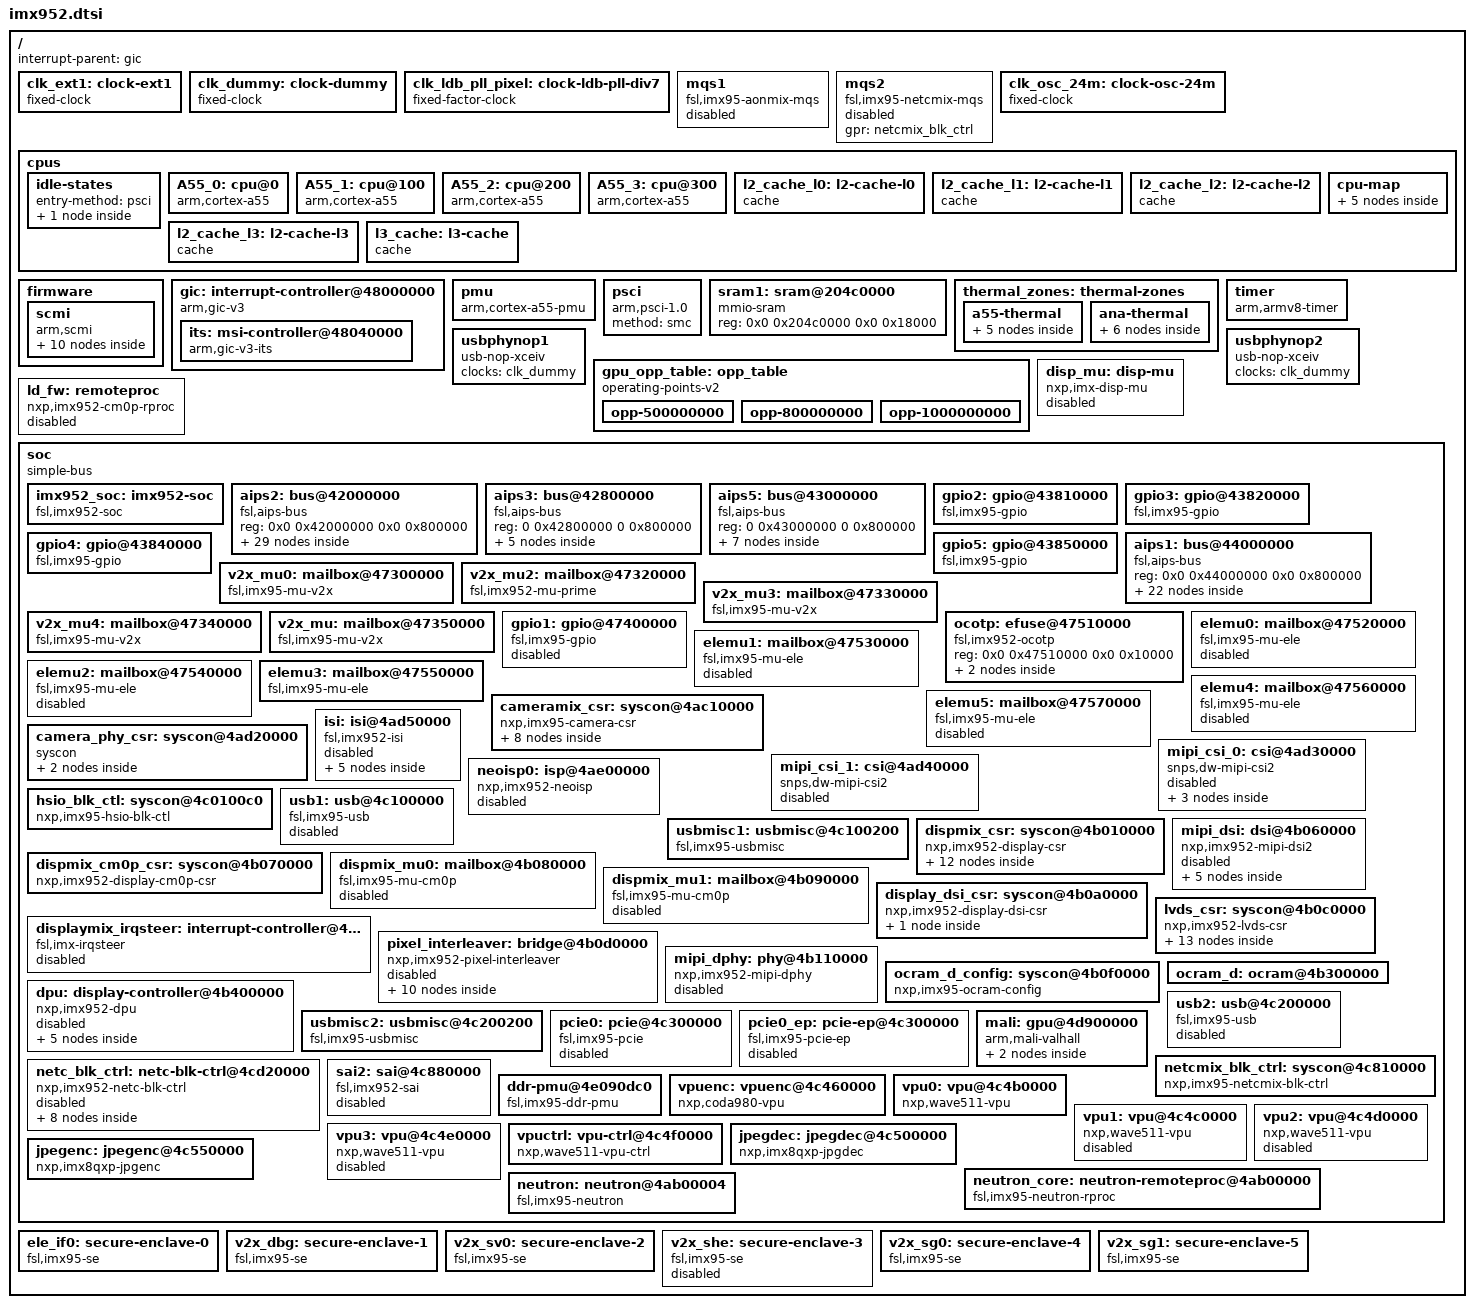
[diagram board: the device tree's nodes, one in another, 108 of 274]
// SPDX-License-Identifier: (GPL-2.0-only OR MIT)
/*
 * Copyright 2025-2026 NXP
 */

#include <dt-bindings/clock/nxp,imx952-clock.h>
#include <dt-bindings/dma/fsl-edma.h>
#include <dt-bindings/gpio/gpio.h>
#include <dt-bindings/interrupt-controller/arm-gic.h>
#include <dt-bindings/thermal/thermal.h>

#include "imx952-clock.h"
#include "imx952-pinfunc.h"
#include "imx952-power.h"

/ {
	interrupt-parent = <&gic>;
	#address-cells = <2>;
	#size-cells = <2>;

	clk_ext1: clock-ext1 {
		compatible = "fixed-clock";
		#clock-cells = <0>;
		clock-frequency = <133000000>;
		clock-output-names = "clk_ext1";
	};

	clk_dummy: clock-dummy {
		compatible = "fixed-clock";
		#clock-cells = <0>;
		clock-frequency = <0>;
		clock-output-names = "dummy";
	};

	clk_ldb_pll_pixel: clock-ldb-pll-div7 {
		compatible = "fixed-factor-clock";
		clocks = <&scmi_clk IMX952_CLK_LDBPLL>;
		#clock-cells = <0>;
		clock-div = <7>;
		clock-mult = <1>;
		clock-output-names = "ldb_pll_div7";
	};

	mqs1: mqs1 {
		compatible = "fsl,imx95-aonmix-mqs";
		status = "disabled";
	};

	mqs2: mqs2 {
		compatible = "fsl,imx95-netcmix-mqs";
		gpr = <&netcmix_blk_ctrl>;
		status = "disabled";
	};

	clk_osc_24m: clock-osc-24m {
		compatible = "fixed-clock";
		#clock-cells = <0>;
		clock-frequency = <24000000>;
		clock-output-names = "osc_24m";
	};

	cpus {
		#address-cells = <1>;
		#size-cells = <0>;

		idle-states {
			entry-method = "psci";

			cpu_pd_wait: cpu-pd-wait {
				compatible = "arm,idle-state";
				arm,psci-suspend-param = <0x0010033>;
				local-timer-stop;
				entry-latency-us = <1000>;
				exit-latency-us = <700>;
				min-residency-us = <2700>;
				wakeup-latency-us = <1500>;
			};
		};

		A55_0: cpu@0 {
			device_type = "cpu";
			compatible = "arm,cortex-a55";
			reg = <0x0>;
			enable-method = "psci";
			#cooling-cells = <2>;
			cpu-idle-states = <&cpu_pd_wait>;
			power-domains = <&scmi_perf IMX952_PERF_A55>;
			power-domain-names = "perf";
			i-cache-size = <32768>;
			i-cache-line-size = <64>;
			i-cache-sets = <128>;
			d-cache-size = <32768>;
			d-cache-line-size = <64>;
			d-cache-sets = <128>;
			next-level-cache = <&l2_cache_l0>;
		};

		A55_1: cpu@100 {
			device_type = "cpu";
			compatible = "arm,cortex-a55";
			reg = <0x100>;
			enable-method = "psci";
			#cooling-cells = <2>;
			cpu-idle-states = <&cpu_pd_wait>;
			power-domains = <&scmi_perf IMX952_PERF_A55>;
			power-domain-names = "perf";
			i-cache-size = <32768>;
			i-cache-line-size = <64>;
			i-cache-sets = <128>;
			d-cache-size = <32768>;
			d-cache-line-size = <64>;
			d-cache-sets = <128>;
			next-level-cache = <&l2_cache_l1>;
		};

		A55_2: cpu@200 {
			device_type = "cpu";
			compatible = "arm,cortex-a55";
			reg = <0x200>;
			enable-method = "psci";
			#cooling-cells = <2>;
			cpu-idle-states = <&cpu_pd_wait>;
			power-domains = <&scmi_perf IMX952_PERF_A55>;
			power-domain-names = "perf";
			i-cache-size = <32768>;
			i-cache-line-size = <64>;
			i-cache-sets = <128>;
			d-cache-size = <32768>;
			d-cache-line-size = <64>;
			d-cache-sets = <128>;
			next-level-cache = <&l2_cache_l2>;
		};

		A55_3: cpu@300 {
			device_type = "cpu";
			compatible = "arm,cortex-a55";
			reg = <0x300>;
			enable-method = "psci";
			#cooling-cells = <2>;
			cpu-idle-states = <&cpu_pd_wait>;
			power-domains = <&scmi_perf IMX952_PERF_A55>;
			power-domain-names = "perf";
			i-cache-size = <32768>;
			i-cache-line-size = <64>;
			i-cache-sets = <128>;
			d-cache-size = <32768>;
			d-cache-line-size = <64>;
			d-cache-sets = <128>;
			next-level-cache = <&l2_cache_l3>;
		};

		l2_cache_l0: l2-cache-l0 {
			compatible = "cache";
			cache-size = <65536>;
			cache-line-size = <64>;
			cache-sets = <256>;
			cache-level = <2>;
			cache-unified;
			next-level-cache = <&l3_cache>;
		};

		l2_cache_l1: l2-cache-l1 {
			compatible = "cache";
			cache-size = <65536>;
			cache-line-size = <64>;
			cache-sets = <256>;
			cache-level = <2>;
			cache-unified;
			next-level-cache = <&l3_cache>;
		};

		l2_cache_l2: l2-cache-l2 {
			compatible = "cache";
			cache-size = <65536>;
			cache-line-size = <64>;
			cache-sets = <256>;
			cache-level = <2>;
			cache-unified;
			next-level-cache = <&l3_cache>;
		};

		l2_cache_l3: l2-cache-l3 {
			compatible = "cache";
			cache-size = <65536>;
			cache-line-size = <64>;
			cache-sets = <256>;
			cache-level = <2>;
			cache-unified;
			next-level-cache = <&l3_cache>;
		};

		l3_cache: l3-cache {
			compatible = "cache";
			cache-size = <524288>;
			cache-line-size = <64>;
			cache-sets = <512>;
			cache-level = <3>;
			cache-unified;
		};

		cpu-map {
			cluster0 {
				core0 {
					cpu = <&A55_0>;
				};

				core1 {
					cpu = <&A55_1>;
				};

				core2 {
					cpu = <&A55_2>;
				};

				core3 {
					cpu = <&A55_3>;
				};
			};
		};
	};

	firmware {
		scmi {
			compatible = "arm,scmi";
			mboxes = <&mu2 5 0>, <&mu2 3 0>, <&mu2 3 1>, <&mu2 5 1>;
			shmem = <&scmi_buf0>, <&scmi_buf1>;
			#address-cells = <1>;
			#size-cells = <0>;
			arm,max-rx-timeout-ms = <5000>;

			scmi_devpd: protocol@11 {
				reg = <0x11>;
				#power-domain-cells = <1>;
			};

			scmi_sys_power: protocol@12 {
				reg = <0x12>;
			};

			scmi_perf: protocol@13 {
				reg = <0x13>;
				#power-domain-cells = <1>;
			};

			scmi_clk: protocol@14 {
				reg = <0x14>;
				#clock-cells = <1>;
			};

			scmi_sensor: protocol@15 {
				reg = <0x15>;
				#thermal-sensor-cells = <1>;
			};

			scmi_iomuxc: protocol@19 {
				reg = <0x19>;
			};

			scmi_lmm: protocol@80 {
				reg = <0x80>;
			};

			scmi_bbm: protocol@81 {
				reg = <0x81>;
			};

			scmi_cpu: protocol@82 {
				reg = <0x82>;
			};

			scmi_misc: protocol@84 {
				reg = <0x84>;
			};
		};
	};

	gic: interrupt-controller@48000000 {
		compatible = "arm,gic-v3";
		reg = <0 0x48000000 0 0x10000>,
		      <0 0x48060000 0 0xc0000>;
		interrupts = <GIC_PPI 9 IRQ_TYPE_LEVEL_HIGH>;
		interrupt-parent = <&gic>;
		interrupt-controller;
		#interrupt-cells = <3>;
		dma-noncoherent;
		#address-cells = <2>;
		#size-cells = <2>;
		ranges;

		its: msi-controller@48040000 {
			compatible = "arm,gic-v3-its";
			reg = <0 0x48040000 0 0x20000>;
			msi-controller;
			#msi-cells = <1>;
			dma-noncoherent;
		};
	};

	pmu {
		compatible = "arm,cortex-a55-pmu";
		interrupts = <GIC_PPI 7 (GIC_CPU_MASK_SIMPLE(6) | IRQ_TYPE_LEVEL_HIGH)>;
	};

	psci {
		compatible = "arm,psci-1.0";
		method = "smc";
	};

	sram1: sram@204c0000 {
		compatible = "mmio-sram";
		reg = <0x0 0x204c0000 0x0 0x18000>;
		ranges = <0x0 0x0 0x204c0000 0x18000>;
		#address-cells = <1>;
		#size-cells = <1>;
	};

	thermal_zones: thermal-zones {
		a55-thermal {
			polling-delay-passive = <250>;
			polling-delay = <2000>;
			thermal-sensors = <&scmi_sensor 1>;
			trips {
				cpu_alert0: trip0 {
					temperature = <105000>;
					hysteresis = <2000>;
					type = "passive";
				};

				cpu_crit0: trip1 {
					temperature = <125000>;
					hysteresis = <2000>;
					type = "critical";
				};
			};

			cooling-maps {
				map0 {
					trip = <&cpu_alert0>;
					cooling-device =
						<&A55_0 THERMAL_NO_LIMIT THERMAL_NO_LIMIT>,
						<&A55_1 THERMAL_NO_LIMIT THERMAL_NO_LIMIT>,
						<&A55_2 THERMAL_NO_LIMIT THERMAL_NO_LIMIT>,
						<&A55_3 THERMAL_NO_LIMIT THERMAL_NO_LIMIT>;
				};
			};
		};

		ana-thermal {
			polling-delay-passive = <250>;
			polling-delay = <2000>;
			thermal-sensors = <&scmi_sensor 0>;
			trips {
				ana_alert: trip0 {
					temperature = <105000>;
					hysteresis = <2000>;
					type = "passive";
				};

				ana_crit0: trip1 {
					temperature = <125000>;
					hysteresis = <2000>;
					type = "critical";
				};
			};

			cooling-maps {
				map0 {
					trip = <&ana_alert>;
					cooling-device =
						<&A55_0 THERMAL_NO_LIMIT THERMAL_NO_LIMIT>,
						<&A55_1 THERMAL_NO_LIMIT THERMAL_NO_LIMIT>,
						<&A55_2 THERMAL_NO_LIMIT THERMAL_NO_LIMIT>,
						<&A55_3 THERMAL_NO_LIMIT THERMAL_NO_LIMIT>,
						<&mali  THERMAL_NO_LIMIT THERMAL_NO_LIMIT>;
				};
				map1 {
					trip = <&ana_crit0>;
					cooling-device = <&mali THERMAL_NO_LIMIT 1>;
				};
			};
		};
	};

	timer {
		compatible = "arm,armv8-timer";
		interrupts = <GIC_PPI 13 (GIC_CPU_MASK_SIMPLE(6) | IRQ_TYPE_LEVEL_LOW)>,
			     <GIC_PPI 14 (GIC_CPU_MASK_SIMPLE(6) | IRQ_TYPE_LEVEL_LOW)>,
			     <GIC_PPI 11 (GIC_CPU_MASK_SIMPLE(6) | IRQ_TYPE_LEVEL_LOW)>,
			     <GIC_PPI 10 (GIC_CPU_MASK_SIMPLE(6) | IRQ_TYPE_LEVEL_LOW)>;
		clock-frequency = <24000000>;
		arm,no-tick-in-suspend;
		interrupt-parent = <&gic>;
	};

	usbphynop1: usbphynop1 {
		compatible = "usb-nop-xceiv";
		#phy-cells = <0>;
		clocks = <&clk_dummy>;
		clock-names = "main_clk";
	};

	usbphynop2: usbphynop2 {
		compatible = "usb-nop-xceiv";
		#phy-cells = <0>;
		clocks = <&clk_dummy>;
		clock-names = "main_clk";
	};

	gpu_opp_table: opp_table {
		compatible = "operating-points-v2", "operating-points-v2-mali";

		opp-500000000 {
			opp-hz = /bits/ 64 <500000000>;
			opp-hz-real = /bits/ 64 <500000000>;
			opp-microvolt = <920000>;
		};

		opp-800000000 {
			opp-hz = /bits/ 64 <800000000>;
			opp-hz-real = /bits/ 64 <800000000>;
			opp-microvolt = <920000>;
		};

		opp-1000000000 {
			opp-hz = /bits/ 64 <1000000000>;
			opp-hz-real = /bits/ 64 <1000000000>;
			opp-microvolt = <920000>;
		};
	};

	disp_mu: disp-mu {
		compatible = "nxp,imx-disp-mu";
		mbox-names = "tx", "rx";
		mboxes = <&dispmix_mu1 0 0>,
			 <&dispmix_mu1 1 0>;
		status = "disabled";
	};

	ld_fw: remoteproc {
		compatible = "nxp,imx952-cm0p-rproc";
		firmware-name = "imx9xm0p_ld_fw.bin";
		clocks = <&dispmix_cm0p_csr IMX952_CLK_CM0P_GATE_SEL>,
			 <&scmi_clk IMX952_CLK_CGC_DISPOCRAM>,
			 <&scmi_clk IMX952_CLK_DISPLPSPI>;
		clock-names = "cm0p", "ocram", "lpspi";
		assigned-clocks = <&scmi_clk IMX952_CLK_DISPLPSPI>;
		assigned-clock-parents = <&scmi_clk IMX952_CLK_SYSPLL1_PFD1_DIV2>;
		assigned-clock-rates = <20000000>;
		power-domains = <&scmi_devpd IMX952_PD_DISPLAY>;
		memory-region = <&ocram_d>;

		nxp,cm0p-ctrl = <&dispmix_cm0p_csr>;
		nxp,ocram-ctrl = <&dispmix_csr>;
		nxp,ocram-cfg = <&ocram_d_config>;

		status = "disabled";
	};

	soc {
		compatible = "simple-bus";
		#address-cells = <2>;
		#size-cells = <2>;
		ranges;

		imx952_soc: imx952-soc {
			compatible = "fsl,imx952-soc";
		};

		aips2: bus@42000000 {
			compatible = "fsl,aips-bus", "simple-bus";
			reg = <0x0 0x42000000 0x0 0x800000>;
			ranges = <0x42000000 0x0 0x42000000 0x8000000>,
				 <0x28000000 0x0 0x28000000 0x10000000>;
			#address-cells = <1>;
			#size-cells = <1>;

			mu7: mailbox@42050000 {
				compatible = "fsl,imx95-mu";
				reg = <0x42050000 0x10000>;
				interrupts = <GIC_SPI 234 IRQ_TYPE_LEVEL_HIGH>;
				clocks = <&scmi_clk IMX952_CLK_BUSWAKEUP>;
				#mbox-cells = <2>;
				status = "disabled";
			};

			wdog3: watchdog@420b0000 {
				compatible = "fsl,imx93-wdt";
				reg = <0x420b0000 0x10000>;
				interrupts = <GIC_SPI 77 IRQ_TYPE_LEVEL_HIGH>;
				clocks = <&scmi_clk IMX952_CLK_BUSWAKEUP>;
				timeout-sec = <40>;
				status = "disabled";
			};

			tpm3: pwm@42100000 {
				compatible = "fsl,imx7ulp-pwm";
				reg = <0x42100000 0x1000>;
				clocks = <&scmi_clk IMX952_CLK_BUSWAKEUP>;
				#pwm-cells = <3>;
				status = "disabled";
			};

			tpm4: pwm@42110000 {
				compatible = "fsl,imx7ulp-pwm";
				reg = <0x42110000 0x1000>;
				clocks = <&scmi_clk IMX952_CLK_TPM4>;
				#pwm-cells = <3>;
				status = "disabled";
			};

			tpm5: pwm@42120000 {
				compatible = "fsl,imx7ulp-pwm";
				reg = <0x42120000 0x1000>;
				clocks = <&scmi_clk IMX952_CLK_TPM5>;
				#pwm-cells = <3>;
				status = "disabled";
			};

			tpm6: pwm@42130000 {
				compatible = "fsl,imx7ulp-pwm";
				reg = <0x42130000 0x1000>;
				clocks = <&scmi_clk IMX952_CLK_TPM6>;
				#pwm-cells = <3>;
				status = "disabled";
			};

			i3c2: i3c@42140000 {
				compatible = "silvaco,i3c-master-v1";
				reg = <0x42140000 0x10000>;
				interrupts = <GIC_SPI 57 IRQ_TYPE_LEVEL_HIGH>;
				#address-cells = <3>;
				#size-cells = <0>;
				clocks = <&scmi_clk IMX952_CLK_BUSWAKEUP>,
					 <&scmi_clk IMX952_CLK_I3C2SLOW>,
					 <&clk_dummy>;
				clock-names = "pclk", "fast_clk", "slow_clk";
				status = "disabled";
			};

			lpi2c3: i2c@42150000 {
				compatible = "fsl,imx95-lpi2c", "fsl,imx7ulp-lpi2c";
				reg = <0x42150000 0x10000>;
				interrupts = <GIC_SPI 58 IRQ_TYPE_LEVEL_HIGH>;
				clocks = <&scmi_clk IMX952_CLK_LPI2C3>,
					 <&scmi_clk IMX952_CLK_BUSWAKEUP>;
				clock-names = "per", "ipg";
				#address-cells = <1>;
				#size-cells = <0>;
				dmas = <&edma2 8 0 0>, <&edma2 9 0 FSL_EDMA_RX>;
				dma-names = "tx", "rx";
				status = "disabled";
			};

			lpi2c4: i2c@42160000 {
				compatible = "fsl,imx95-lpi2c", "fsl,imx7ulp-lpi2c";
				reg = <0x42160000 0x10000>;
				interrupts = <GIC_SPI 59 IRQ_TYPE_LEVEL_HIGH>;
				clocks = <&scmi_clk IMX952_CLK_LPI2C4>,
					 <&scmi_clk IMX952_CLK_BUSWAKEUP>;
				clock-names = "per", "ipg";
				#address-cells = <1>;
				#size-cells = <0>;
				dmas = <&edma2 10 0 0>, <&edma2 11 0 FSL_EDMA_RX>;
				dma-names = "tx", "rx";
				status = "disabled";
			};

			lpspi3: spi@42170000 {
				#address-cells = <1>;
				#size-cells = <0>;
				compatible = "fsl,imx95-spi", "fsl,imx7ulp-spi";
				reg = <0x42170000 0x10000>;
				interrupts = <GIC_SPI 61 IRQ_TYPE_LEVEL_HIGH>;
				clocks = <&scmi_clk IMX952_CLK_LPSPI3>,
					 <&scmi_clk IMX952_CLK_BUSWAKEUP>;
				clock-names = "per", "ipg";
				dmas = <&edma2 12 0 0>, <&edma2 13 0 FSL_EDMA_RX>;
				dma-names = "tx", "rx";
				status = "disabled";
			};

			lpspi4: spi@42180000 {
				#address-cells = <1>;
				#size-cells = <0>;
				compatible = "fsl,imx95-spi", "fsl,imx7ulp-spi";
				reg = <0x42180000 0x10000>;
				interrupts = <GIC_SPI 62 IRQ_TYPE_LEVEL_HIGH>;
				clocks = <&scmi_clk IMX952_CLK_LPSPI4>,
					 <&scmi_clk IMX952_CLK_BUSWAKEUP>;
				clock-names = "per", "ipg";
				dmas = <&edma2 14 0 0>, <&edma2 15 0 FSL_EDMA_RX>;
				dma-names = "tx", "rx";
				status = "disabled";
			};

			lpuart3: serial@42190000 {
				compatible = "fsl,imx95-lpuart", "fsl,imx8ulp-lpuart",
					     "fsl,imx7ulp-lpuart";
				reg = <0x42190000 0x1000>;
				interrupts = <GIC_SPI 64 IRQ_TYPE_LEVEL_HIGH>;
				clocks = <&scmi_clk IMX952_CLK_LPUART3>;
				clock-names = "ipg";
				dmas = <&edma2 18 0 FSL_EDMA_RX>, <&edma2 17 0 0>;
				dma-names = "rx", "tx";
				status = "disabled";
			};

			lpuart4: serial@421a0000 {
				compatible = "fsl,imx95-lpuart", "fsl,imx8ulp-lpuart",
					     "fsl,imx7ulp-lpuart";
				reg = <0x421a0000 0x1000>;
				interrupts = <GIC_SPI 65 IRQ_TYPE_LEVEL_HIGH>;
				clocks = <&scmi_clk IMX952_CLK_LPUART4>;
				clock-names = "ipg";
				dmas = <&edma2 20 0 FSL_EDMA_RX>, <&edma2 19 0 0>;
				dma-names = "rx", "tx";
				status = "disabled";
			};

			lpuart5: serial@421b0000 {
				compatible = "fsl,imx95-lpuart", "fsl,imx8ulp-lpuart",
					     "fsl,imx7ulp-lpuart";
				reg = <0x421b0000 0x1000>;
				interrupts = <GIC_SPI 66 IRQ_TYPE_LEVEL_HIGH>;
				clocks = <&scmi_clk IMX952_CLK_LPUART5>;
				clock-names = "ipg";
				dmas = <&edma2 22 0 FSL_EDMA_RX>, <&edma2 21 0 0>;
				dma-names = "rx", "tx";
				status = "disabled";
			};

			lpuart6: serial@421c0000 {
				compatible = "fsl,imx95-lpuart", "fsl,imx8ulp-lpuart",
					     "fsl,imx7ulp-lpuart";
				reg = <0x421c0000 0x1000>;
				interrupts = <GIC_SPI 67 IRQ_TYPE_LEVEL_HIGH>;
				clocks = <&scmi_clk IMX952_CLK_LPUART6>;
				clock-names = "ipg";
				dmas = <&edma2 24 0 FSL_EDMA_RX>, <&edma2 23 0 0>;
				dma-names = "rx", "tx";
				status = "disabled";
			};

			flexcan2: can@421d0000 {
				compatible = "fsl,imx95-flexcan";
				reg = <0x421d0000 0x10000>;
				interrupts = <GIC_SPI 38 IRQ_TYPE_LEVEL_HIGH>;
				clocks = <&scmi_clk IMX952_CLK_BUSWAKEUP>,
					 <&scmi_clk IMX952_CLK_CAN2>;
				clock-names = "ipg", "per";
				assigned-clocks = <&scmi_clk IMX952_CLK_CAN2>;
				assigned-clock-parents = <&scmi_clk IMX952_CLK_SYSPLL1_PFD1_DIV2>;
				assigned-clock-rates = <40000000>;
				fsl,clk-source = /bits/ 8 <0>;
				status = "disabled";
			};

			flexcan3: can@42220000 {
				compatible = "fsl,imx95-flexcan";
				reg = <0x42220000 0x10000>;
				interrupts = <GIC_SPI 40 IRQ_TYPE_LEVEL_HIGH>;
				clocks = <&scmi_clk IMX952_CLK_BUSWAKEUP>,
					 <&scmi_clk IMX952_CLK_CAN3>;
				clock-names = "ipg", "per";
				assigned-clocks = <&scmi_clk IMX952_CLK_CAN3>;
				assigned-clock-parents = <&scmi_clk IMX952_CLK_SYSPLL1_PFD1_DIV2>;
				assigned-clock-rates = <40000000>;
				fsl,clk-source = /bits/ 8 <0>;
				status = "disabled";
			};

			lpuart7: serial@422b0000 {
				compatible = "fsl,imx95-lpuart", "fsl,imx8ulp-lpuart",
					     "fsl,imx7ulp-lpuart";
				reg = <0x422b0000 0x1000>;
				interrupts = <GIC_SPI 68 IRQ_TYPE_LEVEL_HIGH>;
				clocks = <&scmi_clk IMX952_CLK_LPUART7>;
				clock-names = "ipg";
				dmas = <&edma2 88 0 FSL_EDMA_RX>, <&edma2 87 0 0>;
				dma-names = "rx", "tx";
				status = "disabled";
			};

			lpuart8: serial@422c0000 {
				compatible = "fsl,imx95-lpuart", "fsl,imx8ulp-lpuart",
					     "fsl,imx7ulp-lpuart";
				reg = <0x422c0000 0x1000>;
				interrupts = <GIC_SPI 69 IRQ_TYPE_LEVEL_HIGH>;
				clocks = <&scmi_clk IMX952_CLK_LPUART8>;
				clock-names = "ipg";
				dmas = <&edma2 90 0 FSL_EDMA_RX>, <&edma2 89 0 0>;
				dma-names = "rx", "tx";
				status = "disabled";
			};

			lpi2c5: i2c@422d0000 {
				compatible = "fsl,imx95-lpi2c", "fsl,imx7ulp-lpi2c";
				reg = <0x422d0000 0x10000>;
				interrupts = <GIC_SPI 181 IRQ_TYPE_LEVEL_HIGH>;
				clocks = <&scmi_clk IMX952_CLK_LPI2C5>,
					 <&scmi_clk IMX952_CLK_BUSWAKEUP>;
				clock-names = "per", "ipg";
				#address-cells = <1>;
				#size-cells = <0>;
				dmas = <&edma2 71 0 0>, <&edma2 72 0 FSL_EDMA_RX>;
				dma-names = "tx", "rx";
				status = "disabled";
			};

			lpi2c6: i2c@422e0000 {
				compatible = "fsl,imx95-lpi2c", "fsl,imx7ulp-lpi2c";
				reg = <0x422e0000 0x10000>;
				interrupts = <GIC_SPI 182 IRQ_TYPE_LEVEL_HIGH>;
				clocks = <&scmi_clk IMX952_CLK_LPI2C6>,
					 <&scmi_clk IMX952_CLK_BUSWAKEUP>;
				clock-names = "per", "ipg";
				#address-cells = <1>;
				#size-cells = <0>;
				dmas = <&edma2 73 0 0>, <&edma2 74 0 FSL_EDMA_RX>;
				dma-names = "tx", "rx";
				status = "disabled";
			};

			lpi2c7: i2c@422f0000 {
				compatible = "fsl,imx95-lpi2c", "fsl,imx7ulp-lpi2c";
				reg = <0x422f0000 0x10000>;
				interrupts = <GIC_SPI 183 IRQ_TYPE_LEVEL_HIGH>;
				clocks = <&scmi_clk IMX952_CLK_LPI2C7>,
					 <&scmi_clk IMX952_CLK_BUSWAKEUP>;
				clock-names = "per", "ipg";
				#address-cells = <1>;
				#size-cells = <0>;
				dmas = <&edma2 75 0 0>, <&edma2 76 0 FSL_EDMA_RX>;
				dma-names = "tx", "rx";
				status = "disabled";
			};

			lpi2c8: i2c@42300000 {
				compatible = "fsl,imx95-lpi2c", "fsl,imx7ulp-lpi2c";
				reg = <0x42300000 0x10000>;
				interrupts = <GIC_SPI 184 IRQ_TYPE_LEVEL_HIGH>;
				clocks = <&scmi_clk IMX952_CLK_LPI2C8>,
					 <&scmi_clk IMX952_CLK_BUSWAKEUP>;
				clock-names = "per", "ipg";
				#address-cells = <1>;
				#size-cells = <0>;
				dmas = <&edma2 77 0 0>, <&edma2 78 0 FSL_EDMA_RX>;
				dma-names = "tx", "rx";
				status = "disabled";
			};

			lpspi5: spi@42310000 {
				compatible = "fsl,imx95-spi", "fsl,imx7ulp-spi";
				reg = <0x42310000 0x10000>;
				interrupts = <GIC_SPI 177 IRQ_TYPE_LEVEL_HIGH>;
				#address-cells = <1>;
				#size-cells = <0>;
				clocks = <&scmi_clk IMX952_CLK_LPSPI5>,
					 <&scmi_clk IMX952_CLK_BUSWAKEUP>;
				clock-names = "per", "ipg";
				dmas = <&edma2 79 0 0>, <&edma2 80 0 FSL_EDMA_RX>;
				dma-names = "tx", "rx";
				status = "disabled";
			};

			lpspi6: spi@42320000 {
				compatible = "fsl,imx95-spi", "fsl,imx7ulp-spi";
				reg = <0x42320000 0x10000>;
				interrupts = <GIC_SPI 178 IRQ_TYPE_LEVEL_HIGH>;
				#address-cells = <1>;
				#size-cells = <0>;
				clocks = <&scmi_clk IMX952_CLK_LPSPI6>,
					 <&scmi_clk IMX952_CLK_BUSWAKEUP>;
				clock-names = "per", "ipg";
				dmas = <&edma2 81 0 0>, <&edma2 82 0 FSL_EDMA_RX>;
				dma-names = "tx", "rx";
				status = "disabled";
			};

			lpspi7: spi@42330000 {
				compatible = "fsl,imx95-spi", "fsl,imx7ulp-spi";
				reg = <0x42330000 0x10000>;
				interrupts = <GIC_SPI 179 IRQ_TYPE_LEVEL_HIGH>;
				#address-cells = <1>;
				#size-cells = <0>;
				clocks = <&scmi_clk IMX952_CLK_LPSPI7>,
					 <&scmi_clk IMX952_CLK_BUSWAKEUP>;
				clock-names = "per", "ipg";
				dmas = <&edma2 83 0 0>, <&edma2 84 0 FSL_EDMA_RX>;
				dma-names = "tx", "rx";
				status = "disabled";
			};

			lpspi8: spi@42340000 {
				compatible = "fsl,imx95-spi", "fsl,imx7ulp-spi";
				reg = <0x42340000 0x10000>;
				interrupts = <GIC_SPI 180 IRQ_TYPE_LEVEL_HIGH>;
				#address-cells = <1>;
				#size-cells = <0>;
				clocks = <&scmi_clk IMX952_CLK_LPSPI8>,
					 <&scmi_clk IMX952_CLK_BUSWAKEUP>;
				clock-names = "per", "ipg";
				dmas = <&edma2 85 0 0>, <&edma2 86 0 FSL_EDMA_RX>;
				dma-names = "tx", "rx";
				status = "disabled";
			};

			mu8: mailbox@42350000 {
				compatible = "fsl,imx95-mu";
				reg = <0x42350000 0x10000>;
				interrupts = <GIC_SPI 235 IRQ_TYPE_LEVEL_HIGH>;
				clocks = <&scmi_clk IMX952_CLK_BUSWAKEUP>;
				#mbox-cells = <2>;
				status = "disabled";
			};

			xspi1: spi@42400000 {
				compatible = "nxp,imx952-xspi", "nxp,imx94-xspi";
				reg = <0x42400000 0x50000>, <0x28000000 0x8000000>;
				reg-names = "base", "mmap";
				interrupts = <GIC_SPI 400 IRQ_TYPE_LEVEL_HIGH>,
						<GIC_SPI 401 IRQ_TYPE_LEVEL_HIGH>,
						<GIC_SPI 402 IRQ_TYPE_LEVEL_HIGH>,
						<GIC_SPI 403 IRQ_TYPE_LEVEL_HIGH>,
						<GIC_SPI 404 IRQ_TYPE_LEVEL_HIGH>;
				#address-cells = <1>;
				#size-cells = <0>;
				clocks = <&scmi_clk IMX952_CLK_XSPI1>;
				clock-names = "per";
				assigned-clocks = <&scmi_clk IMX952_CLK_XSPI1>;
				assigned-clock-parents = <&scmi_clk IMX952_CLK_SYSPLL1_PFD1>;
				assigned-clock-rates = <200000000>;
				dmas = <&edma2 53 0 0>, <&edma2 54 0 FSL_EDMA_RX>;
				dma-names = "tx", "rx";
				status = "disabled";
			};
		};

		aips3: bus@42800000 {
			compatible = "fsl,aips-bus", "simple-bus";
			reg = <0 0x42800000 0 0x800000>;
			#address-cells = <1>;
			#size-cells = <1>;
			ranges = <0x42800000 0x0 0x42800000 0x800000>;

			edma2: dma-controller@42800000 {
				compatible = "fsl,imx95-edma5";
				reg = <0x42800000 0x210000>;
				clocks = <&scmi_clk IMX952_CLK_BUSWAKEUP>;
				clock-names = "dma";
				#dma-cells = <3>;
				dma-channels = <64>;
				interrupts = <GIC_SPI 128 IRQ_TYPE_LEVEL_HIGH>,
					     <GIC_SPI 128 IRQ_TYPE_LEVEL_HIGH>,
					     <GIC_SPI 129 IRQ_TYPE_LEVEL_HIGH>,
					     <GIC_SPI 129 IRQ_TYPE_LEVEL_HIGH>,
					     <GIC_SPI 130 IRQ_TYPE_LEVEL_HIGH>,
					     <GIC_SPI 130 IRQ_TYPE_LEVEL_HIGH>,
					     <GIC_SPI 131 IRQ_TYPE_LEVEL_HIGH>,
					     <GIC_SPI 131 IRQ_TYPE_LEVEL_HIGH>,
					     <GIC_SPI 132 IRQ_TYPE_LEVEL_HIGH>,
					     <GIC_SPI 132 IRQ_TYPE_LEVEL_HIGH>,
					     <GIC_SPI 133 IRQ_TYPE_LEVEL_HIGH>,
					     <GIC_SPI 133 IRQ_TYPE_LEVEL_HIGH>,
					     <GIC_SPI 134 IRQ_TYPE_LEVEL_HIGH>,
					     <GIC_SPI 134 IRQ_TYPE_LEVEL_HIGH>,
					     <GIC_SPI 135 IRQ_TYPE_LEVEL_HIGH>,
					     <GIC_SPI 135 IRQ_TYPE_LEVEL_HIGH>,
					     <GIC_SPI 136 IRQ_TYPE_LEVEL_HIGH>,
					     <GIC_SPI 136 IRQ_TYPE_LEVEL_HIGH>,
					     <GIC_SPI 137 IRQ_TYPE_LEVEL_HIGH>,
					     <GIC_SPI 137 IRQ_TYPE_LEVEL_HIGH>,
					     <GIC_SPI 138 IRQ_TYPE_LEVEL_HIGH>,
					     <GIC_SPI 138 IRQ_TYPE_LEVEL_HIGH>,
					     <GIC_SPI 139 IRQ_TYPE_LEVEL_HIGH>,
					     <GIC_SPI 139 IRQ_TYPE_LEVEL_HIGH>,
					     <GIC_SPI 140 IRQ_TYPE_LEVEL_HIGH>,
					     <GIC_SPI 140 IRQ_TYPE_LEVEL_HIGH>,
					     <GIC_SPI 141 IRQ_TYPE_LEVEL_HIGH>,
					     <GIC_SPI 141 IRQ_TYPE_LEVEL_HIGH>,
					     <GIC_SPI 142 IRQ_TYPE_LEVEL_HIGH>,
					     <GIC_SPI 142 IRQ_TYPE_LEVEL_HIGH>,
					     <GIC_SPI 143 IRQ_TYPE_LEVEL_HIGH>,
					     <GIC_SPI 143 IRQ_TYPE_LEVEL_HIGH>,
					     <GIC_SPI 144 IRQ_TYPE_LEVEL_HIGH>,
					     <GIC_SPI 144 IRQ_TYPE_LEVEL_HIGH>,
					     <GIC_SPI 145 IRQ_TYPE_LEVEL_HIGH>,
					     <GIC_SPI 145 IRQ_TYPE_LEVEL_HIGH>,
					     <GIC_SPI 146 IRQ_TYPE_LEVEL_HIGH>,
					     <GIC_SPI 146 IRQ_TYPE_LEVEL_HIGH>,
					     <GIC_SPI 147 IRQ_TYPE_LEVEL_HIGH>,
					     <GIC_SPI 147 IRQ_TYPE_LEVEL_HIGH>,
					     <GIC_SPI 148 IRQ_TYPE_LEVEL_HIGH>,
					     <GIC_SPI 148 IRQ_TYPE_LEVEL_HIGH>,
					     <GIC_SPI 149 IRQ_TYPE_LEVEL_HIGH>,
					     <GIC_SPI 149 IRQ_TYPE_LEVEL_HIGH>,
					     <GIC_SPI 150 IRQ_TYPE_LEVEL_HIGH>,
					     <GIC_SPI 150 IRQ_TYPE_LEVEL_HIGH>,
					     <GIC_SPI 151 IRQ_TYPE_LEVEL_HIGH>,
					     <GIC_SPI 151 IRQ_TYPE_LEVEL_HIGH>,
					     <GIC_SPI 152 IRQ_TYPE_LEVEL_HIGH>,
					     <GIC_SPI 152 IRQ_TYPE_LEVEL_HIGH>,
					     <GIC_SPI 153 IRQ_TYPE_LEVEL_HIGH>,
					     <GIC_SPI 153 IRQ_TYPE_LEVEL_HIGH>,
					     <GIC_SPI 154 IRQ_TYPE_LEVEL_HIGH>,
					     <GIC_SPI 154 IRQ_TYPE_LEVEL_HIGH>,
					     <GIC_SPI 155 IRQ_TYPE_LEVEL_HIGH>,
					     <GIC_SPI 155 IRQ_TYPE_LEVEL_HIGH>,
					     <GIC_SPI 156 IRQ_TYPE_LEVEL_HIGH>,
					     <GIC_SPI 156 IRQ_TYPE_LEVEL_HIGH>,
					     <GIC_SPI 157 IRQ_TYPE_LEVEL_HIGH>,
					     <GIC_SPI 157 IRQ_TYPE_LEVEL_HIGH>,
					     <GIC_SPI 158 IRQ_TYPE_LEVEL_HIGH>,
					     <GIC_SPI 158 IRQ_TYPE_LEVEL_HIGH>,
					     <GIC_SPI 159 IRQ_TYPE_LEVEL_HIGH>,
					     <GIC_SPI 159 IRQ_TYPE_LEVEL_HIGH>,
					     <GIC_SPI 127 IRQ_TYPE_LEVEL_HIGH>; //error irq
			};

			edma3: dma-controller@42a10000 {
				compatible = "fsl,imx952-acp-edma5";
				reg = <0x42a10000 0x210000>;
				clocks = <&scmi_clk IMX952_CLK_BUSWAKEUP>;
				clock-names = "dma";
				#dma-cells = <3>;
				dma-channels = <64>;
				dma-coherent;
				interrupts = <GIC_SPI 256 IRQ_TYPE_LEVEL_HIGH>,
					     <GIC_SPI 256 IRQ_TYPE_LEVEL_HIGH>,
					     <GIC_SPI 257 IRQ_TYPE_LEVEL_HIGH>,
					     <GIC_SPI 257 IRQ_TYPE_LEVEL_HIGH>,
					     <GIC_SPI 258 IRQ_TYPE_LEVEL_HIGH>,
					     <GIC_SPI 258 IRQ_TYPE_LEVEL_HIGH>,
					     <GIC_SPI 259 IRQ_TYPE_LEVEL_HIGH>,
					     <GIC_SPI 259 IRQ_TYPE_LEVEL_HIGH>,
					     <GIC_SPI 260 IRQ_TYPE_LEVEL_HIGH>,
					     <GIC_SPI 260 IRQ_TYPE_LEVEL_HIGH>,
					     <GIC_SPI 261 IRQ_TYPE_LEVEL_HIGH>,
					     <GIC_SPI 261 IRQ_TYPE_LEVEL_HIGH>,
					     <GIC_SPI 262 IRQ_TYPE_LEVEL_HIGH>,
					     <GIC_SPI 262 IRQ_TYPE_LEVEL_HIGH>,
					     <GIC_SPI 263 IRQ_TYPE_LEVEL_HIGH>,
					     <GIC_SPI 263 IRQ_TYPE_LEVEL_HIGH>,
					     <GIC_SPI 264 IRQ_TYPE_LEVEL_HIGH>,
					     <GIC_SPI 264 IRQ_TYPE_LEVEL_HIGH>,
					     <GIC_SPI 265 IRQ_TYPE_LEVEL_HIGH>,
					     <GIC_SPI 265 IRQ_TYPE_LEVEL_HIGH>,
					     <GIC_SPI 266 IRQ_TYPE_LEVEL_HIGH>,
					     <GIC_SPI 266 IRQ_TYPE_LEVEL_HIGH>,
					     <GIC_SPI 267 IRQ_TYPE_LEVEL_HIGH>,
					     <GIC_SPI 267 IRQ_TYPE_LEVEL_HIGH>,
					     <GIC_SPI 268 IRQ_TYPE_LEVEL_HIGH>,
					     <GIC_SPI 268 IRQ_TYPE_LEVEL_HIGH>,
					     <GIC_SPI 269 IRQ_TYPE_LEVEL_HIGH>,
					     <GIC_SPI 269 IRQ_TYPE_LEVEL_HIGH>,
					     <GIC_SPI 270 IRQ_TYPE_LEVEL_HIGH>,
					     <GIC_SPI 270 IRQ_TYPE_LEVEL_HIGH>,
					     <GIC_SPI 271 IRQ_TYPE_LEVEL_HIGH>,
					     <GIC_SPI 271 IRQ_TYPE_LEVEL_HIGH>,
					     <GIC_SPI 272 IRQ_TYPE_LEVEL_HIGH>,
					     <GIC_SPI 272 IRQ_TYPE_LEVEL_HIGH>,
					     <GIC_SPI 273 IRQ_TYPE_LEVEL_HIGH>,
					     <GIC_SPI 273 IRQ_TYPE_LEVEL_HIGH>,
					     <GIC_SPI 274 IRQ_TYPE_LEVEL_HIGH>,
					     <GIC_SPI 274 IRQ_TYPE_LEVEL_HIGH>,
					     <GIC_SPI 275 IRQ_TYPE_LEVEL_HIGH>,
					     <GIC_SPI 275 IRQ_TYPE_LEVEL_HIGH>,
					     <GIC_SPI 276 IRQ_TYPE_LEVEL_HIGH>,
					     <GIC_SPI 276 IRQ_TYPE_LEVEL_HIGH>,
					     <GIC_SPI 277 IRQ_TYPE_LEVEL_HIGH>,
					     <GIC_SPI 277 IRQ_TYPE_LEVEL_HIGH>,
					     <GIC_SPI 278 IRQ_TYPE_LEVEL_HIGH>,
					     <GIC_SPI 278 IRQ_TYPE_LEVEL_HIGH>,
					     <GIC_SPI 279 IRQ_TYPE_LEVEL_HIGH>,
					     <GIC_SPI 279 IRQ_TYPE_LEVEL_HIGH>,
					     <GIC_SPI 280 IRQ_TYPE_LEVEL_HIGH>,
					     <GIC_SPI 280 IRQ_TYPE_LEVEL_HIGH>,
					     <GIC_SPI 281 IRQ_TYPE_LEVEL_HIGH>,
					     <GIC_SPI 281 IRQ_TYPE_LEVEL_HIGH>,
					     <GIC_SPI 282 IRQ_TYPE_LEVEL_HIGH>,
					     <GIC_SPI 282 IRQ_TYPE_LEVEL_HIGH>,
					     <GIC_SPI 283 IRQ_TYPE_LEVEL_HIGH>,
					     <GIC_SPI 283 IRQ_TYPE_LEVEL_HIGH>,
					     <GIC_SPI 284 IRQ_TYPE_LEVEL_HIGH>,
					     <GIC_SPI 284 IRQ_TYPE_LEVEL_HIGH>,
					     <GIC_SPI 285 IRQ_TYPE_LEVEL_HIGH>,
					     <GIC_SPI 285 IRQ_TYPE_LEVEL_HIGH>,
					     <GIC_SPI 286 IRQ_TYPE_LEVEL_HIGH>,
					     <GIC_SPI 286 IRQ_TYPE_LEVEL_HIGH>,
					     <GIC_SPI 287 IRQ_TYPE_LEVEL_HIGH>,
					     <GIC_SPI 287 IRQ_TYPE_LEVEL_HIGH>,
					     <GIC_SPI 250 IRQ_TYPE_LEVEL_HIGH>;
			};

			usdhc1: mmc@42c20000 {
				compatible = "fsl,imx952-usdhc", "fsl,imx8mm-usdhc";
				reg = <0x42c20000 0x10000>;
				interrupts = <GIC_SPI 86 IRQ_TYPE_LEVEL_HIGH>;
				clocks = <&scmi_clk IMX952_CLK_BUSWAKEUP>,
					 <&scmi_clk IMX952_CLK_WAKEUPAXI>,
					 <&scmi_clk IMX952_CLK_USDHC1>;
				clock-names = "ipg", "ahb", "per";
				assigned-clocks = <&scmi_clk IMX952_CLK_USDHC1>;
				assigned-clock-parents = <&scmi_clk IMX952_CLK_SYSPLL1_PFD1>;
				assigned-clock-rates = <400000000>;
				bus-width = <8>;
				fsl,tuning-start-tap = <1>;
				fsl,tuning-step= <2>;
				status = "disabled";
			};

			usdhc2: mmc@42c30000 {
				compatible = "fsl,imx952-usdhc", "fsl,imx8mm-usdhc";
				reg = <0x42c30000 0x10000>;
				interrupts = <GIC_SPI 87 IRQ_TYPE_LEVEL_HIGH>;
				clocks = <&scmi_clk IMX952_CLK_BUSWAKEUP>,
					 <&scmi_clk IMX952_CLK_WAKEUPAXI>,
					 <&scmi_clk IMX952_CLK_USDHC2>;
				clock-names = "ipg", "ahb", "per";
				assigned-clocks = <&scmi_clk IMX952_CLK_USDHC2>;
				assigned-clock-parents = <&scmi_clk IMX952_CLK_SYSPLL1_PFD1>;
				assigned-clock-rates = <200000000>;
				bus-width = <4>;
				fsl,tuning-start-tap = <1>;
				fsl,tuning-step= <2>;
				status = "disabled";
			};

			usdhc3: mmc@42c40000 {
				compatible = "fsl,imx952-usdhc", "fsl,imx8mm-usdhc";
				reg = <0x42c40000 0x10000>;
				interrupts = <GIC_SPI 191 IRQ_TYPE_LEVEL_HIGH>;
				clocks = <&scmi_clk IMX952_CLK_BUSWAKEUP>,
					 <&scmi_clk IMX952_CLK_WAKEUPAXI>,
					 <&scmi_clk IMX952_CLK_USDHC3>;
				clock-names = "ipg", "ahb", "per";
				bus-width = <4>;
				fsl,tuning-start-tap = <1>;
				fsl,tuning-step = <2>;
				status = "disabled";
			};
		};

		aips5: bus@43000000 {
			compatible = "fsl,aips-bus", "simple-bus";
			reg = <0 0x43000000 0 0x800000>;
			#address-cells = <1>;
			#size-cells = <1>;
			ranges = <0x43000000 0x0 0x43000000 0x800000>;

			asrc1: asrc@43000000 {
				compatible = "fsl,imx952-asrc";
				reg = <0x43000000 0x10000>;
				interrupts = <GIC_SPI 376 IRQ_TYPE_LEVEL_HIGH>;
				clocks = <&scmi_clk IMX952_CLK_BUSWAKEUP>,
					 <&scmi_clk IMX952_CLK_BUSWAKEUP>,
					 <&scmi_clk IMX952_CLK_ASRC1>,
					 <&scmi_clk IMX952_CLK_ASRC2>,
					 <&clk_dummy>,
					 <&clk_dummy>,
					 <&clk_dummy>,
					 <&clk_dummy>,
					 <&clk_dummy>,
					 <&clk_dummy>,
					 <&clk_dummy>,
					 <&clk_dummy>,
					 <&clk_dummy>,
					 <&clk_dummy>,
					 <&clk_dummy>,
					 <&clk_dummy>,
					 <&clk_dummy>,
					 <&clk_dummy>,
					 <&clk_dummy>;
				clock-names = "mem", "ipg",
					      "asrck_0", "asrck_1", "asrck_2", "asrck_3",
					      "asrck_4", "asrck_5", "asrck_6", "asrck_7",
					      "asrck_8", "asrck_9", "asrck_a", "asrck_b",
					      "asrck_c", "asrck_d", "asrck_e", "asrck_f",
					      "spba";
				dmas = <&edma2 97 0 0>, <&edma2 98 0 0>, <&edma2 99 0 0>,
				       <&edma2 100 0 FSL_EDMA_RX>, <&edma2 101 0 FSL_EDMA_RX>,
				       <&edma2 102 0 FSL_EDMA_RX>;
				/* tx* is output channel of asrc, it is rx channel for eDMA */
				dma-names = "rxa", "rxb", "rxc",
					    "txa", "txb", "txc";
				#sound-dai-cells = <0>;
				fsl,asrc-rate  = <8000>;
				fsl,asrc-width = <16>;
				status = "disabled";
			};

			asrc2: asrc@430f0000 {
				compatible = "fsl,imx952-asrc";
				reg = <0x430f0000 0x10000>;
				interrupts = <GIC_SPI 384 IRQ_TYPE_LEVEL_HIGH>;
				clocks = <&scmi_clk IMX952_CLK_BUSWAKEUP>,
					 <&scmi_clk IMX952_CLK_BUSWAKEUP>,
					 <&scmi_clk IMX952_CLK_ASRC1>,
					 <&scmi_clk IMX952_CLK_ASRC2>,
					 <&clk_dummy>,
					 <&clk_dummy>,
					 <&clk_dummy>,
					 <&clk_dummy>,
					 <&clk_dummy>,
					 <&clk_dummy>,
					 <&clk_dummy>,
					 <&clk_dummy>,
					 <&clk_dummy>,
					 <&clk_dummy>,
					 <&clk_dummy>,
					 <&clk_dummy>,
					 <&clk_dummy>,
					 <&clk_dummy>,
					 <&clk_dummy>;
				clock-names = "mem", "ipg",
					      "asrck_0", "asrck_1", "asrck_2", "asrck_3",
					      "asrck_4", "asrck_5", "asrck_6", "asrck_7",
					      "asrck_8", "asrck_9", "asrck_a", "asrck_b",
					      "asrck_c", "asrck_d", "asrck_e", "asrck_f",
					      "spba";
				dmas = <&edma2 103 0 0>, <&edma2 104 0 0>, <&edma2 105 0 0>,
				       <&edma2 106 0 FSL_EDMA_RX>, <&edma2 107 0 FSL_EDMA_RX>,
				       <&edma2 108 0 FSL_EDMA_RX>;
				/* tx* is output channel of asrc, it is rx channel for eDMA */
				dma-names = "rxa", "rxb", "rxc",
					    "txa", "txb", "txc";
				#sound-dai-cells = <0>;
				fsl,asrc-rate  = <8000>;
				fsl,asrc-width = <16>;
				status = "disabled";
			};

			amix: amix@431f0000 {
				compatible = "fsl,imx952-audmix";
				reg = <0x431f0000 0x10000>;
				clocks = <&scmi_clk IMX952_CLK_AUDMIX1>;
				clock-names = "ipg";
				status = "disabled";
			};

			sai3: sai@433e0000 {
				compatible = "fsl,imx952-sai", "fsl,imx95-sai";
				reg = <0x433e0000 0x10000>;
				interrupts = <GIC_SPI 170 IRQ_TYPE_LEVEL_HIGH>;
				clocks = <&scmi_clk IMX952_CLK_BUSWAKEUP>, <&clk_dummy>,
					 <&scmi_clk IMX952_CLK_SAI3>, <&clk_dummy>,
					 <&clk_dummy>;
				clock-names = "bus", "mclk0", "mclk1", "mclk2", "mclk3";
				dmas = <&edma2 61 0 FSL_EDMA_RX>, <&edma2 60 0 0>;
				dma-names = "rx", "tx";
				#sound-dai-cells = <0>;
				status = "disabled";
			};

			sai4: sai@433f0000 {
				compatible = "fsl,imx952-sai", "fsl,imx95-sai";
				reg = <0x433f0000 0x10000>;
				interrupts = <GIC_SPI 171 IRQ_TYPE_LEVEL_HIGH>;
				clocks = <&scmi_clk IMX952_CLK_BUSWAKEUP>, <&clk_dummy>,
					 <&scmi_clk IMX952_CLK_SAI4>, <&clk_dummy>,
					 <&clk_dummy>;
				clock-names = "bus", "mclk0", "mclk1", "mclk2", "mclk3";
				dmas = <&edma2 68 0 FSL_EDMA_RX>, <&edma2 67 0 0>;
				dma-names = "rx", "tx";
				#sound-dai-cells = <0>;
				status = "disabled";
			};

			sai5: sai@43400000 {
				compatible = "fsl,imx952-sai", "fsl,imx95-sai";
				reg = <0x43400000 0x10000>;
				interrupts = <GIC_SPI 172 IRQ_TYPE_LEVEL_HIGH>;
				clocks = <&scmi_clk IMX952_CLK_BUSWAKEUP>, <&clk_dummy>,
					 <&scmi_clk IMX952_CLK_SAI5>, <&clk_dummy>,
					 <&clk_dummy>;
				clock-names = "bus", "mclk0", "mclk1", "mclk2", "mclk3";
				dmas = <&edma2 70 0 FSL_EDMA_RX>, <&edma2 69 0 0>;
				dma-names = "rx", "tx";
				#sound-dai-cells = <0>;
				status = "disabled";
			};

			sai6: sai@43410000 {
				compatible = "fsl,imx952-sai", "fsl,imx95-sai";
				reg = <0x43410000 0x10000>;
				interrupts = <GIC_SPI 399 IRQ_TYPE_LEVEL_HIGH>;
				clocks = <&scmi_clk IMX952_CLK_BUSWAKEUP>, <&clk_dummy>,
					 <&scmi_clk IMX952_CLK_SAI3>, <&clk_dummy>,
					 <&clk_dummy>;
				clock-names = "bus", "mclk0", "mclk1", "mclk2", "mclk3";
				dmas = <&edma2 96 0 FSL_EDMA_RX>, <&edma2 95 0 0>;
				dma-names = "rx", "tx";
				#sound-dai-cells = <0>;
				status = "disabled";
			};
		};

		gpio2: gpio@43810000 {
			compatible = "fsl,imx95-gpio", "fsl,imx8ulp-gpio";
			reg = <0x0 0x43810000 0x0 0x1000>;
			gpio-controller;
			#gpio-cells = <2>;
			interrupts = <GIC_SPI 49 IRQ_TYPE_LEVEL_HIGH>,
				     <GIC_SPI 50 IRQ_TYPE_LEVEL_HIGH>;
			interrupt-controller;
			#interrupt-cells = <2>;
			clocks = <&scmi_clk IMX952_CLK_BUSWAKEUP>,
				 <&scmi_clk IMX952_CLK_BUSWAKEUP>;
			clock-names = "gpio", "port";
			gpio-ranges = <&scmi_iomuxc 0 4 32>;
			ngpios = <32>;
		};

		gpio3: gpio@43820000 {
			compatible = "fsl,imx95-gpio", "fsl,imx8ulp-gpio";
			reg = <0x0 0x43820000 0x0 0x1000>;
			gpio-controller;
			#gpio-cells = <2>;
			interrupts = <GIC_SPI 51 IRQ_TYPE_LEVEL_HIGH>,
				     <GIC_SPI 52 IRQ_TYPE_LEVEL_HIGH>;
			interrupt-controller;
			#interrupt-cells = <2>;
			clocks = <&scmi_clk IMX952_CLK_BUSWAKEUP>,
				 <&scmi_clk IMX952_CLK_BUSWAKEUP>;
			clock-names = "gpio", "port";
			gpio-ranges = <&scmi_iomuxc 0 115 8>, <&scmi_iomuxc 8 85 18>,
				      <&scmi_iomuxc 26 53 2>, <&scmi_iomuxc 28 0 4>;
			ngpios = <32>;
		};

		gpio4: gpio@43840000 {
			compatible = "fsl,imx95-gpio", "fsl,imx8ulp-gpio";
			reg = <0x0 0x43840000 0x0 0x1000>;
			gpio-controller;
			#gpio-cells = <2>;
			interrupts = <GIC_SPI 53 IRQ_TYPE_LEVEL_HIGH>,
				     <GIC_SPI 54 IRQ_TYPE_LEVEL_HIGH>;
			interrupt-controller;
			#interrupt-cells = <2>;
			clocks = <&scmi_clk IMX952_CLK_BUSWAKEUP>,
				 <&scmi_clk IMX952_CLK_BUSWAKEUP>;
			clock-names = "gpio", "port";
			gpio-ranges = <&scmi_iomuxc 0 57 28>, <&scmi_iomuxc 28 55 2>;
			ngpios = <30>;
		};

		gpio5: gpio@43850000 {
			compatible = "fsl,imx95-gpio", "fsl,imx8ulp-gpio";
			reg = <0x0 0x43850000 0x0 0x1000>;
			gpio-controller;
			#gpio-cells = <2>;
			interrupts = <GIC_SPI 55 IRQ_TYPE_LEVEL_HIGH>,
				     <GIC_SPI 56 IRQ_TYPE_LEVEL_HIGH>;
			interrupt-controller;
			#interrupt-cells = <2>;
			clocks = <&scmi_clk IMX952_CLK_BUSWAKEUP>,
				 <&scmi_clk IMX952_CLK_BUSWAKEUP>;
			clock-names = "gpio", "port";
			gpio-ranges = <&scmi_iomuxc 0 103 12>, <&scmi_iomuxc 12 36 9>;
			ngpios = <21>;
		};

		aips1: bus@44000000 {
			compatible = "fsl,aips-bus", "simple-bus";
			reg = <0x0 0x44000000 0x0 0x800000>;
			ranges = <0x44000000 0x0 0x44000000 0x800000>;
			#address-cells = <1>;
			#size-cells = <1>;

			edma1: dma-controller@44000000 {
				compatible = "fsl,imx93-edma3";
				reg = <0x44000000 0x210000>;
				clocks = <&scmi_clk IMX952_CLK_BUSAON>;
				clock-names = "dma";
				#dma-cells = <3>;
				dma-channels = <32>;
				interrupts = <GIC_SPI 96 IRQ_TYPE_LEVEL_HIGH>,
					     <GIC_SPI 97 IRQ_TYPE_LEVEL_HIGH>,
					     <GIC_SPI 98 IRQ_TYPE_LEVEL_HIGH>,
					     <GIC_SPI 99 IRQ_TYPE_LEVEL_HIGH>,
					     <GIC_SPI 100 IRQ_TYPE_LEVEL_HIGH>,
					     <GIC_SPI 101 IRQ_TYPE_LEVEL_HIGH>,
					     <GIC_SPI 102 IRQ_TYPE_LEVEL_HIGH>,
					     <GIC_SPI 103 IRQ_TYPE_LEVEL_HIGH>,
					     <GIC_SPI 104 IRQ_TYPE_LEVEL_HIGH>,
					     <GIC_SPI 105 IRQ_TYPE_LEVEL_HIGH>,
					     <GIC_SPI 106 IRQ_TYPE_LEVEL_HIGH>,
					     <GIC_SPI 107 IRQ_TYPE_LEVEL_HIGH>,
					     <GIC_SPI 108 IRQ_TYPE_LEVEL_HIGH>,
					     <GIC_SPI 109 IRQ_TYPE_LEVEL_HIGH>,
					     <GIC_SPI 110 IRQ_TYPE_LEVEL_HIGH>,
					     <GIC_SPI 111 IRQ_TYPE_LEVEL_HIGH>,
					     <GIC_SPI 112 IRQ_TYPE_LEVEL_HIGH>,
					     <GIC_SPI 113 IRQ_TYPE_LEVEL_HIGH>,
					     <GIC_SPI 114 IRQ_TYPE_LEVEL_HIGH>,
					     <GIC_SPI 115 IRQ_TYPE_LEVEL_HIGH>,
					     <GIC_SPI 116 IRQ_TYPE_LEVEL_HIGH>,
					     <GIC_SPI 117 IRQ_TYPE_LEVEL_HIGH>,
					     <GIC_SPI 118 IRQ_TYPE_LEVEL_HIGH>,
					     <GIC_SPI 119 IRQ_TYPE_LEVEL_HIGH>,
					     <GIC_SPI 120 IRQ_TYPE_LEVEL_HIGH>,
					     <GIC_SPI 121 IRQ_TYPE_LEVEL_HIGH>,
					     <GIC_SPI 122 IRQ_TYPE_LEVEL_HIGH>,
					     <GIC_SPI 123 IRQ_TYPE_LEVEL_HIGH>,
					     <GIC_SPI 124 IRQ_TYPE_LEVEL_HIGH>,
					     <GIC_SPI 125 IRQ_TYPE_LEVEL_HIGH>,
					     <GIC_SPI 126 IRQ_TYPE_LEVEL_HIGH>,
					     <GIC_SPI 126 IRQ_TYPE_LEVEL_HIGH>,
					     <GIC_SPI 95 IRQ_TYPE_LEVEL_HIGH>; //error irq
			};

			mu1: mailbox@44220000 {
				compatible = "fsl,imx95-mu";
				reg = <0x44220000 0x10000>;
				interrupts = <GIC_SPI 224 IRQ_TYPE_LEVEL_HIGH>;
				clocks = <&scmi_clk IMX952_CLK_BUSAON>;
				#mbox-cells = <2>;
				status = "disabled";
			};

			system_counter: timer@44290000 {
				compatible = "nxp,imx95-sysctr-timer";
				reg = <0x44290000 0x30000>;
				interrupts = <GIC_SPI 72 IRQ_TYPE_LEVEL_HIGH>;
				clocks = <&clk_osc_24m>;
				clock-names = "per";
				nxp,no-divider;
			};

			i3c1: i3c@44330000 {
				compatible = "silvaco,i3c-master-v1";
				reg = <0x44330000 0x10000>;
				interrupts = <GIC_SPI 12 IRQ_TYPE_LEVEL_HIGH>;
				#address-cells = <3>;
				#size-cells = <0>;
				clocks = <&scmi_clk IMX952_CLK_BUSAON>,
					 <&scmi_clk IMX952_CLK_I3C1SLOW>,
					 <&clk_dummy>;
				clock-names = "pclk", "fast_clk", "slow_clk";
				status = "disabled";
			};

			lpi2c1: i2c@44340000 {
				compatible = "fsl,imx95-lpi2c", "fsl,imx7ulp-lpi2c";
				reg = <0x44340000 0x10000>;
				interrupts = <GIC_SPI 13 IRQ_TYPE_LEVEL_HIGH>;
				clocks = <&scmi_clk IMX952_CLK_LPI2C1>,
					 <&scmi_clk IMX952_CLK_BUSAON>;
				clock-names = "per", "ipg";
				#address-cells = <1>;
				#size-cells = <0>;
				dmas = <&edma1 12 0 0>, <&edma1 13 0 FSL_EDMA_RX> ;
				dma-names = "tx", "rx";
				status = "disabled";
			};

			lpi2c2: i2c@44350000 {
				compatible = "fsl,imx95-lpi2c", "fsl,imx7ulp-lpi2c";
				reg = <0x44350000 0x10000>;
				interrupts = <GIC_SPI 14 IRQ_TYPE_LEVEL_HIGH>;
				clocks = <&scmi_clk IMX952_CLK_LPI2C2>,
					 <&scmi_clk IMX952_CLK_BUSAON>;
				clock-names = "per", "ipg";
				#address-cells = <1>;
				#size-cells = <0>;
				dmas = <&edma1 14 0 0>, <&edma1 15 0 FSL_EDMA_RX> ;
				dma-names = "tx", "rx";
				status = "disabled";
			};

			lpspi1: spi@44360000 {
				compatible = "fsl,imx95-spi", "fsl,imx7ulp-spi";
				reg = <0x44360000 0x10000>;
				interrupts = <GIC_SPI 16 IRQ_TYPE_LEVEL_HIGH>;
				clocks = <&scmi_clk IMX952_CLK_LPSPI1>,
					 <&scmi_clk IMX952_CLK_BUSAON>;
				clock-names = "per", "ipg";
				#address-cells = <1>;
				#size-cells = <0>;
				dmas = <&edma1 16 0 FSL_EDMA_RX>, <&edma1 17 0 0> ;
				dma-names = "tx", "rx";
				status = "disabled";
			};

			lpspi2: spi@44370000 {
				compatible = "fsl,imx95-spi", "fsl,imx7ulp-spi";
				reg = <0x44370000 0x10000>;
				interrupts = <GIC_SPI 17 IRQ_TYPE_LEVEL_HIGH>;
				clocks = <&scmi_clk IMX952_CLK_LPSPI2>,
					 <&scmi_clk IMX952_CLK_BUSAON>;
				clock-names = "per", "ipg";
				#address-cells = <1>;
				#size-cells = <0>;
				dmas = <&edma1 18 0 FSL_EDMA_RX>, <&edma1 19 0 0> ;
				dma-names = "tx", "rx";
				status = "disabled";
			};

			lpuart1: serial@44380000 {
				compatible = "fsl,imx95-lpuart", "fsl,imx8ulp-lpuart",
					     "fsl,imx7ulp-lpuart";
				reg = <0x44380000 0x1000>;
				interrupts = <GIC_SPI 19 IRQ_TYPE_LEVEL_HIGH>;
				clocks = <&scmi_clk IMX952_CLK_LPUART1>;
				clock-names = "ipg";
				dmas = <&edma1 21 0 FSL_EDMA_RX>, <&edma1 20 0 0>;
				dma-names = "rx", "tx";
				status = "disabled";
			};

			lpuart2: serial@44390000 {
				compatible = "fsl,imx95-lpuart", "fsl,imx8ulp-lpuart",
					     "fsl,imx7ulp-lpuart";
				reg = <0x44390000 0x1000>;
				interrupts = <GIC_SPI 20 IRQ_TYPE_LEVEL_HIGH>;
				clocks = <&scmi_clk IMX952_CLK_LPUART2>;
				clock-names = "ipg";
				dmas = <&edma1 23 0 FSL_EDMA_RX>, <&edma1 22 0 0>;
				dma-names = "rx", "tx";
				status = "disabled";
			};

			flexcan1: can@443a0000 {
				compatible = "fsl,imx95-flexcan";
				reg = <0x443a0000 0x10000>;
				interrupts = <GIC_SPI 8 IRQ_TYPE_LEVEL_HIGH>;
				clocks = <&scmi_clk IMX952_CLK_BUSAON>,
					 <&scmi_clk IMX952_CLK_CAN1>;
				clock-names = "ipg", "per";
				assigned-clocks = <&scmi_clk IMX952_CLK_CAN1>;
				assigned-clock-parents = <&scmi_clk IMX952_CLK_SYSPLL1_PFD1_DIV2>;
				assigned-clock-rates = <40000000>;
				fsl,clk-source = /bits/ 8 <0>;
				status = "disabled";
			};

			sai1: sai@443b0000 {
				compatible = "fsl,imx952-sai", "fsl,imx95-sai";
				reg = <0x443b0000 0x10000>;
				interrupts = <GIC_SPI 34 IRQ_TYPE_LEVEL_HIGH>;
				clocks = <&scmi_clk IMX952_CLK_BUSAON>, <&clk_dummy>,
					 <&scmi_clk IMX952_CLK_SAI1>, <&clk_dummy>,
					 <&clk_dummy>;
				clock-names = "bus", "mclk0", "mclk1", "mclk2", "mclk3";
				dmas = <&edma1 25 0 FSL_EDMA_RX>, <&edma1 24 0 0>;
				dma-names = "rx", "tx";
				#sound-dai-cells = <0>;
				status = "disabled";
			};

			micfil: micfil@44520000 {
				compatible = "fsl,imx943-micfil";
				reg = <0x44520000 0x10000>;
				interrupts = <GIC_SPI 188 IRQ_TYPE_LEVEL_HIGH>,
					     <GIC_SPI 187 IRQ_TYPE_LEVEL_HIGH>,
					     <GIC_SPI 186 IRQ_TYPE_LEVEL_HIGH>,
					     <GIC_SPI 185 IRQ_TYPE_LEVEL_HIGH>;
				clocks = <&scmi_clk IMX952_CLK_BUSAON>,
					 <&scmi_clk IMX952_CLK_PDM>,
					 <&scmi_clk IMX952_CLK_AUDIOPLL1>,
					 <&scmi_clk IMX952_CLK_AUDIOPLL2>,
					 <&clk_dummy>;
				clock-names = "ipg_clk", "ipg_clk_app",
					      "pll8k", "pll11k", "clkext3";
				dmas = <&edma1 6 0 (FSL_EDMA_MULTI_FIFO | FSL_EDMA_RX)>;
				dma-names = "rx";
				#sound-dai-cells = <0>;
				status = "disabled";
			};

			adc1: adc@44530000 {
				compatible = "nxp,imx93-adc";
				reg = <0x44530000 0x10000>;
				interrupts = <GIC_SPI 199 IRQ_TYPE_LEVEL_HIGH>,
					     <GIC_SPI 200 IRQ_TYPE_LEVEL_HIGH>,
					     <GIC_SPI 201 IRQ_TYPE_LEVEL_HIGH>;
				clocks = <&scmi_clk IMX952_CLK_ADC>;
				clock-names = "ipg";
				#io-channel-cells = <1>;
				status = "disabled";
			};

			mu2: mailbox@445b0000 {
				compatible = "fsl,imx95-mu";
				reg = <0x445b0000 0x1000>;
				ranges;
				interrupts = <GIC_SPI 226 IRQ_TYPE_LEVEL_HIGH>;
				#address-cells = <1>;
				#size-cells = <1>;
				#mbox-cells = <2>;

				sram0: sram@445b1000 {
					compatible = "mmio-sram";
					reg = <0x445b1000 0x400>;
					ranges = <0x0 0x445b1000 0x400>;
					#address-cells = <1>;
					#size-cells = <1>;

					scmi_buf0: scmi-sram-section@0 {
						compatible = "arm,scmi-shmem";
						reg = <0x0 0x80>;
					};

					scmi_buf1: scmi-sram-section@80 {
						compatible = "arm,scmi-shmem";
						reg = <0x80 0x80>;
					};
				};

			};

			mu3: mailbox@445d0000 {
				compatible = "fsl,imx95-mu";
				reg = <0x445d0000 0x10000>;
				interrupts = <GIC_SPI 228 IRQ_TYPE_LEVEL_HIGH>;
				clocks = <&scmi_clk IMX952_CLK_BUSAON>;
				#mbox-cells = <2>;
				status = "disabled";
			};

			mu4: mailbox@445f0000 {
				compatible = "fsl,imx95-mu";
				reg = <0x445f0000 0x10000>;
				interrupts = <GIC_SPI 230 IRQ_TYPE_LEVEL_HIGH>;
				clocks = <&scmi_clk IMX952_CLK_BUSAON>;
				#mbox-cells = <2>;
				status = "disabled";
			};

			mu5: mailbox@44610000 {
				compatible = "fsl,imx95-mu";
				reg = <0x44610000 0x10000>;
				interrupts = <GIC_SPI 205 IRQ_TYPE_LEVEL_HIGH>;
				clocks = <&scmi_clk IMX952_CLK_BUSAON>;
				#mbox-cells = <2>;
				status = "disabled";
			};

			mu6: mailbox@44630000 {
				compatible = "fsl,imx95-mu";
				reg = <0x44630000 0x10000>;
				interrupts = <GIC_SPI 206 IRQ_TYPE_LEVEL_HIGH>;
				clocks = <&scmi_clk IMX952_CLK_BUSAON>;
				#mbox-cells = <2>;
				status = "disabled";
			};
		};

		v2x_mu0: mailbox@47300000 {
			compatible = "fsl,imx95-mu-v2x";
			reg = <0x0 0x47300000 0x0 0x10000>;
			interrupts = <GIC_SPI 27 IRQ_TYPE_LEVEL_HIGH>;
			interrupt-names = "tx", "rx";
			#mbox-cells = <2>;
		};

		v2x_mu2: mailbox@47320000 {
			compatible = "fsl,imx952-mu-prime";
			reg = <0x0 0x47320000 0x0 0x10000>,
			      <0x0 0x42C80000 0x0 0x200>;
			reg-names = "prime", "atu";
			interrupts = <GIC_SPI 254 IRQ_TYPE_LEVEL_HIGH>;
			interrupt-names = "tx", "rx";
			#mbox-cells = <2>;
		};

		v2x_mu3: mailbox@47330000 {
			compatible = "fsl,imx95-mu-v2x";
			reg = <0x0 0x47330000 0x0 0x10000>;
			interrupts = <GIC_SPI 28 IRQ_TYPE_LEVEL_HIGH>;
			interrupt-names = "tx", "rx";
			#mbox-cells = <2>;
		};

		v2x_mu4: mailbox@47340000 {
			compatible = "fsl,imx95-mu-v2x";
			reg = <0x0 0x47340000 0x0 0x10000>;
			interrupts = <GIC_SPI 239 IRQ_TYPE_LEVEL_HIGH>;
			interrupt-names = "tx", "rx";
			#mbox-cells = <2>;
		};

		v2x_mu: mailbox@47350000 {
			compatible = "fsl,imx95-mu-v2x";
			reg = <0x0 0x47350000 0x0 0x10000>;
			interrupts = <GIC_SPI 255 IRQ_TYPE_LEVEL_HIGH>;
			interrupt-names = "tx", "rx";
			#mbox-cells = <2>;
		};

		/* GPIO1 is under exclusive control of System Manager */
		gpio1: gpio@47400000 {
			compatible = "fsl,imx95-gpio", "fsl,imx8ulp-gpio";
			reg = <0x0 0x47400000 0x0 0x1000>;
			gpio-controller;
			#gpio-cells = <2>;
			interrupts = <GIC_SPI 10 IRQ_TYPE_LEVEL_HIGH>,
				     <GIC_SPI 11 IRQ_TYPE_LEVEL_HIGH>;
			interrupt-controller;
			#interrupt-cells = <2>;
			clocks = <&scmi_clk IMX952_CLK_M33>,
				 <&scmi_clk IMX952_CLK_M33>;
			clock-names = "gpio", "port";
			gpio-ranges = <&scmi_iomuxc 0 123 16>;
			ngpios = <16>;
			status = "disabled";
		};

		ocotp: efuse@47510000 {
			compatible = "fsl,imx952-ocotp";
			reg = <0x0 0x47510000 0x0 0x10000>;
			#address-cells = <1>;
			#size-cells = <1>;

			eth_mac0: mac-address@0 {
				reg = <0x0514 0x6>;
			};

			eth_mac1: mac-address@1 {
				reg = <0x1514 0x6>;
			};
		};

		elemu0: mailbox@47520000 {
			compatible = "fsl,imx95-mu-ele";
			reg = <0x0 0x47520000 0x0 0x10000>;
			interrupts = <GIC_SPI 21 IRQ_TYPE_LEVEL_HIGH>;
			#mbox-cells = <2>;
			status = "disabled";
		};

		elemu1: mailbox@47530000 {
			compatible = "fsl,imx95-mu-ele";
			reg = <0x0 0x47530000 0x0 0x10000>;
			interrupts = <GIC_SPI 22 IRQ_TYPE_LEVEL_HIGH>;
			#mbox-cells = <2>;
			status = "disabled";
		};

		elemu2: mailbox@47540000 {
			compatible = "fsl,imx95-mu-ele";
			reg = <0x0 0x47540000 0x0 0x10000>;
			interrupts = <GIC_SPI 23 IRQ_TYPE_LEVEL_HIGH>;
			#mbox-cells = <2>;
			status = "disabled";
		};

		elemu3: mailbox@47550000 {
			compatible = "fsl,imx95-mu-ele";
			reg = <0x0 0x47550000 0x0 0x10000>;
			interrupts = <GIC_SPI 24 IRQ_TYPE_LEVEL_HIGH>;
			#mbox-cells = <2>;
		};

		elemu4: mailbox@47560000 {
			compatible = "fsl,imx95-mu-ele";
			reg = <0x0 0x47560000 0x0 0x10000>;
			interrupts = <GIC_SPI 25 IRQ_TYPE_LEVEL_HIGH>;
			#mbox-cells = <2>;
			status = "disabled";
		};

		elemu5: mailbox@47570000 {
			compatible = "fsl,imx95-mu-ele";
			reg = <0x0 0x47570000 0x0 0x10000>;
			interrupts = <GIC_SPI 26 IRQ_TYPE_LEVEL_HIGH>;
			#mbox-cells = <2>;
			status = "disabled";
		};

		cameramix_csr: syscon@4ac10000 {
			compatible = "nxp,imx95-camera-csr", "syscon";
			#address-cells = <1>;
			#size-cells = <1>;
			reg = <0x0 0x4ac10000 0x0 0x10000>;
			#clock-cells = <1>;
			clocks = <&scmi_clk IMX952_CLK_CAMAPB>;
			power-domains = <&scmi_devpd IMX952_PD_CAMERA>;

			csi_pixel_formatter_0: formatter@20 {
				compatible = "fsl,imx95-csi-formatter";
				reg = <0x20 0x100>;
				clocks = <&cameramix_csr IMX952_CLK_CAMBLK_CSI2_FOR0>;
				power-domains = <&scmi_devpd IMX952_PD_CAMERA>;
				nxp,neoisp = <&neoisp0>;
				status = "disabled";

				ports {
					#address-cells = <1>;
					#size-cells = <0>;

					port@0 {
						reg = <0>;
					};

					port@1 {
						reg = <1>;
					};
				};
			};

			csi_pixel_formatter_1: formatter@120 {
				compatible = "fsl,imx95-csi-formatter";
				reg = <0x120 0x100>;
				clocks = <&cameramix_csr IMX952_CLK_CAMBLK_CSI2_FOR1>;
				power-domains = <&scmi_devpd IMX952_PD_CAMERA>;
				nxp,neoisp = <&neoisp0>;
				status = "disabled";

				ports {
					#address-cells = <1>;
					#size-cells = <0>;

					port@0 {
						reg = <0>;
					};

					port@1 {
						reg = <1>;
					};
				};
			};
		};

		camera_phy_csr: syscon@4ad20000 {
			compatible = "syscon", "simple-mfd";
			reg = <0x0 0x4ad20000 0x0 0x10000>;
			#address-cells = <1>;
			#size-cells = <1>;
			clocks = <&scmi_clk IMX952_CLK_CAMAPB>;

			dphy_rx_0: dphy-rx@0 {
				compatible = "fsl,imx952-dphy-rx";
				#phy-cells = <0>;
				power-domains = <&scmi_devpd IMX952_PD_CAMERA>;
				status = "disabled";
			};

			dphy_rx_1: dphy-rx@100 {
				compatible = "fsl,imx952-dphy-rx";
				reg = <0x100 0x10>;
				clocks = <&scmi_clk IMX952_CLK_CAMPHYCFG>,
					 <&scmi_clk IMX952_CLK_CGC_CAMCSI0>;
				clock-names = "phy_cfg", "csi0";
				assigned-clocks = <&scmi_clk IMX952_CLK_CAMPHYCFG>;
				assigned-clock-parents = <&scmi_clk IMX952_CLK_OSC24M>;
				assigned-clock-rates = <24000000>;
				#phy-cells = <0>;
				fsl,csis = <&mipi_csi_1>;
				power-domains = <&scmi_devpd IMX952_PD_CAMERA>;
				status = "disabled";
			};
		};

		mipi_csi_0: csi@4ad30000 {
			compatible = "snps,dw-mipi-csi2", "syscon";
			reg = <0x0 0x4ad30000 0x0 0x10000>;
			interrupts = <GIC_SPI 374 IRQ_TYPE_LEVEL_HIGH>;
			clocks = <&scmi_clk IMX952_CLK_CGC_CAMCSI0>;
			clock-names = "per";
			phys = <&dphy_rx_0>;
			phy-names = "dphy-rx";
			power-domains = <&scmi_devpd IMX952_PD_CAMERA>;
			status = "disabled";

			ports {
				#address-cells = <1>;
				#size-cells = <0>;

				port@0 {
					reg = <0>;
				};

				port@1 {
					reg = <1>;
				};
			};
		};

		mipi_csi_1: csi@4ad40000 {
			compatible = "snps,dw-mipi-csi2", "syscon";
			reg = <0x0 0x4ad40000 0x0 0x10000>;
			interrupts = <GIC_SPI 375 IRQ_TYPE_LEVEL_HIGH>;
			clocks = <&scmi_clk IMX952_CLK_CGC_CAMCSI1>;
			clock-names = "per";
			phys = <&dphy_rx_1>;
			phy-names = "dphy-rx";
			power-domains = <&scmi_devpd IMX952_PD_CAMERA>;
			status = "disabled";
		};

		isi: isi@4ad50000 {
			compatible = "fsl,imx952-isi";
			reg = <0x0 0x4ad50000 0x0 0x80000>;
			interrupts = <GIC_SPI 221 IRQ_TYPE_LEVEL_HIGH>,
				     <GIC_SPI 344 IRQ_TYPE_LEVEL_HIGH>,
				     <GIC_SPI 345 IRQ_TYPE_LEVEL_HIGH>,
				     <GIC_SPI 346 IRQ_TYPE_LEVEL_HIGH>,
				     <GIC_SPI 347 IRQ_TYPE_LEVEL_HIGH>,
				     <GIC_SPI 348 IRQ_TYPE_LEVEL_HIGH>,
				     <GIC_SPI 349 IRQ_TYPE_LEVEL_HIGH>,
				     <GIC_SPI 350 IRQ_TYPE_LEVEL_HIGH>;
			clocks = <&scmi_clk IMX952_CLK_CAMAPB>,
				 <&scmi_clk IMX952_CLK_CGC_CAMISI>;
			clock-names = "apb", "axi";
			fsl,blk-ctrl = <&cameramix_csr>;
			power-domains = <&scmi_devpd IMX952_PD_CAMERA>;
			status = "disabled";

			ports {
				#address-cells = <1>;
				#size-cells = <0>;

				port@0 {
					reg = <0>;
				};

				port@1 {
					reg = <1>;
				};

				port@2 {
					reg = <2>;
				};

				port@3 {
					reg = <3>;
				};
			};
		};

		neoisp0: isp@4ae00000 {
			compatible = "nxp,imx952-neoisp";
			reg = <0x0 0x4ae00000 0x0 0x8000>,
			      <0x0 0x4afe0000 0x0 0x10000>;
			reg-names = "registers", "stats";
			interrupts = <GIC_SPI 222 IRQ_TYPE_LEVEL_HIGH>;
			interrupt-parent = <&gic>;
			clocks = <&cameramix_csr IMX952_CLK_CAMBLK_ISP_AXI>,
				 <&cameramix_csr IMX952_CLK_CAMBLK_ISP_PIXEL>,
				 <&cameramix_csr IMX952_CLK_CAMBLK_ISP>,
				 <&scmi_clk IMX952_CLK_CGC_CAMISP>;
			clock-names = "camblk_isp_axi",
				      "camblk_isp_pixel",
				      "camblk_isp",
				      "cgc_camisp";
			power-domains = <&scmi_devpd IMX952_PD_CAMERA>;
			nxp,blk-ctrl = <&cameramix_csr>;
			status = "disabled";
		};

		hsio_blk_ctl: syscon@4c0100c0 {
			compatible = "nxp,imx95-hsio-blk-ctl", "syscon";
			reg = <0x0 0x4c0100c0 0x0 0x1>;
			#clock-cells = <1>;
			power-domains = <&scmi_devpd IMX952_PD_HSIO_TOP>;
			clocks = <&clk_dummy>;
		};

		usb1: usb@4c100000 {
			compatible = "fsl,imx95-usb", "fsl,imx7d-usb", "fsl,imx27-usb";
			reg = <0x0 0x4c100000 0x0 0x200>;
			interrupts = <GIC_SPI 175 IRQ_TYPE_LEVEL_HIGH>,
				     <GIC_SPI 173 IRQ_TYPE_LEVEL_HIGH>;
			clocks = <&scmi_clk IMX952_CLK_CGC_HSIOUSB>,
				 <&scmi_clk IMX952_CLK_OSC32K>;
			clock-names = "usb_ctrl_root", "usb_wakeup";
			power-domains = <&scmi_devpd IMX952_PD_HSIO_TOP>;
			phys = <&usbphynop1>;
			fsl,usbmisc = <&usbmisc1 0>;
			status = "disabled";
		};

		usbmisc1: usbmisc@4c100200 {
			compatible = "fsl,imx95-usbmisc", "fsl,imx7d-usbmisc", "fsl,imx6q-usbmisc";
			#index-cells = <1>;
			reg = <0x0 0x4c100200 0x0 0x200>,
			      <0x0 0x4c010010 0x0 0x4>;
		};

		dispmix_csr: syscon@4b010000 {
			compatible = "nxp,imx952-display-csr", "syscon";
			reg = <0x0 0x4b010000 0x0 0x10000>;
			#address-cells = <1>;
			#size-cells = <1>;
			clocks = <&scmi_clk IMX952_CLK_DISPAPB>;
			power-domains = <&scmi_devpd IMX952_PD_DISPLAY>;
			assigned-clocks = <&scmi_clk IMX952_CLK_DISPAXI>,
					  <&scmi_clk IMX952_CLK_DISPAPB>,
					  <&scmi_clk IMX952_CLK_CGC_DISPOCRAM>;
			assigned-clock-parents = <&scmi_clk IMX952_CLK_SYSPLL1_PFD1>,
						 <&scmi_clk IMX952_CLK_SYSPLL1_PFD1_DIV2>;
			assigned-clock-rates = <400000000>, <133333333>, <400000000>;

			display_pixel_link: bridge@c {
				compatible = "nxp,imx952-dc-pixel-link";
				reg = <0xc 0x4>;
				status = "disabled";

				ports {
					#address-cells = <1>;
					#size-cells = <0>;

					port@0 {
						reg = <0>;

						display_pixel_link0_to_pixel_interleaver_disp0: endpoint {
							remote-endpoint = <&pixel_interleaver_disp0_to_display_pixel_link0>;
						};
					};

					port@1 {
						reg = <1>;

						display_pixel_link1_to_pixel_interleaver_disp1: endpoint {
							remote-endpoint = <&pixel_interleaver_disp1_to_display_pixel_link1>;
						};
					};

					port@2 {
						#address-cells = <1>;
						#size-cells = <0>;
						reg = <2>;

						display_pixel_link0_to_mipi_dsi: endpoint@0 {
							reg = <0>;
							remote-endpoint = <&mipi_dsi_to_display_pixel_link0>;
						};

						display_pixel_link0_to_ldb_ch0: endpoint@1 {
							reg = <1>;
							remote-endpoint = <&ldb_ch0_to_display_pixel_link0>;
						};
					};

					port@3 {
						#address-cells = <1>;
						#size-cells = <0>;
						reg = <3>;

						display_pixel_link1_to_mipi_dsi: endpoint@0 {
							reg = <0>;
							remote-endpoint = <&mipi_dsi_to_display_pixel_link1>;
						};

						display_pixel_link1_to_ldb_ch1: endpoint@1 {
							reg = <1>;
							remote-endpoint = <&ldb_ch1_to_display_pixel_link1>;
						};
					};
				};
			};
		};

		mipi_dsi: dsi@4b060000 {
			compatible = "nxp,imx952-mipi-dsi2";
			reg = <0x0 0x4b060000 0x0 0x10000>;
			clocks = <&scmi_clk IMX952_CLK_MIPIPHYPLLBYPASS>,
				 <&scmi_clk IMX952_CLK_CGC_DISPDSI>,
				 <&scmi_clk IMX952_CLK_DISP1PIX>,
				 <&scmi_clk IMX952_CLK_DISP1PIX>,
				 <&mipi_dphy>;
			clock-names = "bypass", "pclk", "sys", "pix", "phy_pll";
			assigned-clocks = <&scmi_clk IMX952_CLK_MIPIPHYPLLBYPASS>,
					  <&scmi_clk IMX952_CLK_CGC_DISPDSI>;
			assigned-clock-parents = <&scmi_clk IMX952_CLK_VIDEOPLL1>,
						 <&scmi_clk IMX952_CLK_DISPAPB>;
			mux-controls = <&mux 0>;
			power-domains = <&scmi_devpd IMX952_PD_DISPLAY>;
			nxp,display-dsi-csr = <&display_dsi_csr>;
			phys = <&mipi_dphy>;
			phy-names = "dphy";
			status = "disabled";

			ports {
				#address-cells = <1>;
				#size-cells = <0>;

				port@0 {
					#address-cells = <1>;
					#size-cells = <0>;
					reg = <0>;

					mipi_dsi_to_display_pixel_link0: endpoint@0 {
						reg = <0>;
						remote-endpoint = <&display_pixel_link0_to_mipi_dsi>;
					};

					mipi_dsi_to_display_pixel_link1: endpoint@1 {
						reg = <1>;
						remote-endpoint = <&display_pixel_link1_to_mipi_dsi>;
					};
				};

				port@1 {
					reg = <1>;
				};
			};
		};

		dispmix_cm0p_csr: syscon@4b070000 {
			compatible = "nxp,imx952-display-cm0p-csr", "syscon";
			#address-cells = <1>;
			#size-cells = <1>;
			reg = <0x0 0x4b070000 0x0 0x10000>;
			#clock-cells = <1>;
			clocks = <&scmi_clk IMX952_CLK_DISPAPB>;
			power-domains = <&scmi_devpd IMX952_PD_DISPLAY>;
		};

		dispmix_mu0: mailbox@4b080000 {
			compatible = "fsl,imx95-mu-cm0p";
			reg = <0x0 0x4b080000 0x0 0x10000>;
			interrupts = <GIC_SPI 408 IRQ_TYPE_LEVEL_HIGH>;
			interrupt-names = "tx", "rx";
			#mbox-cells = <2>;
			power-domains = <&scmi_devpd IMX952_PD_DISPLAY>;
			status = "disabled";
		};

		dispmix_mu1: mailbox@4b090000 {
			compatible = "fsl,imx95-mu-cm0p";
			reg = <0x0 0x4b090000 0x0 0x10000>;
			interrupts = <GIC_SPI 409 IRQ_TYPE_LEVEL_HIGH>;
			interrupt-names = "tx", "rx";
			#mbox-cells = <2>;
			power-domains = <&scmi_devpd IMX952_PD_DISPLAY>;
			status = "disabled";
		};

		display_dsi_csr: syscon@4b0a0000 {
			compatible = "nxp,imx952-display-dsi-csr", "syscon";
			reg = <0x0 0x4b0a0000 0x0 0x10000>;
			#clock-cells = <1>;
			clocks = <&scmi_clk IMX952_CLK_DISPAPB>;
			power-domains = <&scmi_devpd IMX952_PD_DISPLAY>;

			mux: mux-controller {
				compatible = "mmio-mux";
				#mux-control-cells = <1>;
				mux-reg-masks = <0x4 0x00000001>; /* PXL_LINK_SEL */
				idle-states = <0>;
			};
		};

		displaymix_irqsteer: interrupt-controller@4b0b0000 {
			compatible = "fsl,imx-irqsteer";
			reg = <0x0 0x4b0b0000 0x0 0x1000>;
			interrupts = <GIC_SPI 214 IRQ_TYPE_LEVEL_HIGH>,
				     <GIC_SPI 215 IRQ_TYPE_LEVEL_HIGH>,
				     <GIC_SPI 216 IRQ_TYPE_LEVEL_HIGH>,
				     <GIC_SPI 217 IRQ_TYPE_LEVEL_HIGH>,
				     <GIC_SPI 218 IRQ_TYPE_LEVEL_HIGH>,
				     <GIC_SPI 312 IRQ_TYPE_LEVEL_HIGH>,	/* reserved */
				     <GIC_SPI 312 IRQ_TYPE_LEVEL_HIGH>,	/* reserved */
				     <GIC_SPI 219 IRQ_TYPE_LEVEL_HIGH>;
			power-domains = <&scmi_devpd IMX952_PD_DISPLAY>;
			clocks = <&scmi_clk IMX952_CLK_DISPAPB>;
			clock-names = "ipg";
			fsl,channel = <0>;
			fsl,num-irqs = <512>;
			interrupt-controller;
			#interrupt-cells = <1>;
			status = "disabled";
		};

		lvds_csr: syscon@4b0c0000 {
			compatible = "nxp,imx952-lvds-csr", "nxp,imx95-lvds-csr", "syscon";
			#address-cells = <1>;
			#size-cells = <1>;
			reg = <0x0 0x4b0c0000 0x0 0x10000>;
			#clock-cells = <1>;
			clocks = <&scmi_clk IMX952_CLK_DISPAPB>;
			power-domains = <&scmi_devpd IMX952_PD_DISPLAY>;

			ldb: ldb@4 {
				compatible = "fsl,imx952-ldb", "fsl,imx95-ldb";
				#address-cells = <1>;
				#size-cells = <0>;
				reg = <0x4 0x4>;
				clocks = <&lvds_csr IMX952_CLK_DISPMIX_PIX_DI0_GATE>,
					 <&lvds_csr IMX952_CLK_DISPMIX_PIX_DI1_GATE>,
					 <&lvds_csr IMX952_CLK_DISPMIX_LVDS_CH0_GATE>,
					 <&lvds_csr IMX952_CLK_DISPMIX_LVDS_CH1_GATE>,
					 <&scmi_clk IMX952_CLK_LDBPLL>;
				clock-names = "ldb_di0", "ldb_di1", "ldb_ch0", "ldb_ch1", "ldb_pll";
				status = "disabled";

				channel@0 {
					#address-cells = <1>;
					#size-cells = <0>;
					reg = <0>;
					phys = <&ldb0_phy1>;
					phy-names = "lvds_phy";
					status = "disabled";

					port@0 {
						reg = <0>;

						ldb_ch0_to_display_pixel_link0: endpoint {
							remote-endpoint = <&display_pixel_link0_to_ldb_ch0>;
						};
					};

					port@1 {
						reg = <1>;
					};
				};

				channel@1 {
					#address-cells = <1>;
					#size-cells = <0>;
					reg = <1>;
					phys = <&ldb1_phy1>;
					phy-names = "lvds_phy";
					status = "disabled";

					port@0 {
						reg = <0>;

						ldb_ch1_to_display_pixel_link1: endpoint {
							remote-endpoint = <&display_pixel_link1_to_ldb_ch1>;
						};
					};

					port@1 {
						reg = <1>;
					};
				};
			};

			ldb0_phy: phy@8 {
				compatible = "fsl,imx952-lvds0-phy", "fsl,imx95-lvds0-phy";
				#address-cells = <1>;
				#size-cells = <0>;
				reg = <0x8 0x4>;
				gpr = <&lvds_csr>;
				clocks = <&scmi_clk IMX952_CLK_DISPAPB>;
				clock-names = "apb";
				power-domains = <&scmi_devpd IMX952_PD_DISPLAY>;
				status = "disabled";

				ldb0_phy1: port@0 {
					reg = <0>;
					#phy-cells = <0>;
				};
			};

			ldb1_phy: phy@c {
				compatible = "fsl,imx952-lvds1-phy", "fsl,imx95-lvds1-phy";
				#address-cells = <1>;
				#size-cells = <0>;
				reg = <0xc 0x4>;
				gpr = <&lvds_csr>;
				clocks = <&scmi_clk IMX952_CLK_DISPAPB>;
				clock-names = "apb";
				power-domains = <&scmi_devpd IMX952_PD_DISPLAY>;
				status = "disabled";

				ldb1_phy1: port@0 {
					reg = <0>;
					#phy-cells = <0>;
				};
			};
		};

		pixel_interleaver: bridge@4b0d0000 {
			compatible = "nxp,imx952-pixel-interleaver";
			#address-cells = <1>;
			#size-cells = <0>;
			reg = <0x0 0x4b0d0000 0x0 0x20000>;
			interrupt-parent = <&displaymix_irqsteer>;
			interrupts = <62>;
			clocks = <&scmi_clk IMX952_CLK_CGC_DISPSEERIS>;
			nxp,blk-ctrl = <&dispmix_csr>;
			status = "disabled";

			channel@0 {
				#address-cells = <1>;
				#size-cells = <0>;
				reg = <0>;
				status = "disabled";

				port@0 {
					reg = <0>;

					pixel_interleaver_disp0_to_dpu_disp0: endpoint {
						remote-endpoint = <&dpu_disp0_to_pixel_interleaver_disp0>;
					};
				};

				port@1 {
					reg = <1>;

					pixel_interleaver_disp0_to_display_pixel_link0: endpoint {
						remote-endpoint = <&display_pixel_link0_to_pixel_interleaver_disp0>;
					};
				};
			};

			channel@1 {
				#address-cells = <1>;
				#size-cells = <0>;
				reg = <1>;
				status = "disabled";

				port@0 {
					reg = <0>;

					pixel_interleaver_disp1_to_dpu_disp1: endpoint {
						remote-endpoint = <&dpu_disp1_to_pixel_interleaver_disp1>;
					};
				};

				port@1 {
					reg = <1>;

					pixel_interleaver_disp1_to_display_pixel_link1: endpoint {
						remote-endpoint = <&display_pixel_link1_to_pixel_interleaver_disp1>;
					};
				};
			};
		};

		mipi_dphy: phy@4b110000 {
			compatible = "nxp,imx952-mipi-dphy";
			reg = <0x0 0x4b110000 0x0 0x40000>;
			#clock-cells = <0>;
			clocks = <&scmi_clk IMX952_CLK_DISPCDPHYAPB>,
				 <&scmi_clk IMX952_CLK_DISPPHYCFG>,
				 <&scmi_clk IMX952_CLK_DISPPHYCFG>;
			clock-names = "apb", "cfg", "ref";
			assigned-clocks = <&scmi_clk IMX952_CLK_DISPPHYCFG>;
			assigned-clock-parents = <&scmi_clk IMX952_CLK_OSC24M>;
			nxp,blk-ctrl = <&display_dsi_csr>;
			#phy-cells = <0>;
			power-domains = <&scmi_devpd IMX952_PD_DISPLAY>;
			status = "disabled";
		};

		ocram_d_config: syscon@4b0f0000 {
			compatible = "nxp,imx95-ocram-config", "syscon";
			reg = <0x0 0x4b0f0000 0x0 0x10000>;
			power-domains = <&scmi_devpd IMX952_PD_DISPLAY>;
		};

		ocram_d: ocram@4b300000 {
			reg = <0x0 0x4b300000 0x0 0x4000>;
			no-map;
		};

		dpu: display-controller@4b400000 {
			compatible = "nxp,imx952-dpu";
			reg = <0x0 0x4b400000 0x0 0x400000>;
			interrupt-parent = <&displaymix_irqsteer>;
			interrupts = <448>, <449>, <450>,  <64>,
				      <65>,  <66>,  <67>,  <68>,
				      <69>, <192>, <193>, <194>,
				     <195>, <196>, <197>,  <70>,
				      <71>,  <72>,  <73>,  <74>,
				      <75>,  <76>,  <77>,  <78>,
				      <79>,  <80>,  <81>,  <82>,
				      <83>,  <84>,  <85>,  <86>,
				      <87>,  <88>,  <89>, <198>,
				     <199>, <200>, <201>, <202>,
				     <203>, <204>, <205>, <206>,
				     <207>, <208>, <209>, <210>,
				     <211>, <212>, <213>, <214>,
				     <451>,   <1>,   <2>,   <3>,
				       <4>,  <90>,  <91>,  <92>,
				      <93>,  <94>,  <95>,  <96>,
				      <97>,  <98>,  <99>, <100>,
				     <101>, <102>, <103>, <215>,
				     <216>, <217>, <218>, <219>,
				     <220>, <221>, <222>, <223>,
				     <224>, <225>, <226>, <227>,
				     <228>;
			interrupt-names = "store9_shdload",
					  "store9_framecomplete",
					  "store9_seqcomplete",
					  "extdst0_shdload",
					  "extdst0_framecomplete",
					  "extdst0_seqcomplete",
					  "extdst4_shdload",
					  "extdst4_framecomplete",
					  "extdst4_seqcomplete",
					  "extdst1_shdload",
					  "extdst1_framecomplete",
					  "extdst1_seqcomplete",
					  "extdst5_shdload",
					  "extdst5_framecomplete",
					  "extdst5_seqcomplete",
					  "domainblend0_shdload",
					  "domainblend0_framecomplete",
					  "disengcfg_shdload0",
					  "disengcfg_framecomplete0",
					  "disengcfg_seqcomplete0",
					  "framegen0_int0",
					  "framegen0_int1",
					  "framegen0_int2",
					  "framegen0_int3",
					  "sig0_shdload",
					  "sig0_valid",
					  "sig0_error",
					  "sig0_cluster_error",
					  "sig0_cluster_match",
					  "idhash0_shdload",
					  "idhash0_valid",
					  "idhash0_window_error",
					  "localdimming0_irq0",
					  "localdimming0_irq1",
					  "localdimming0_irq2",
					  "domainblend1_shdload",
					  "domainblend1_framecomplete",
					  "disengcfg_shdload1",
					  "disengcfg_framecomplete1",
					  "disengcfg_seqcomplete1",
					  "framegen1_int0",
					  "framegen1_int1",
					  "framegen1_int2",
					  "framegen1_int3",
					  "sig1_shdload",
					  "sig1_valid",
					  "sig1_error",
					  "sig1_cluster_error",
					  "sig1_cluster_match",
					  "idhash1_shdload",
					  "idhash1_valid",
					  "idhash1_window_error",
					  "cmdseq_error",
					  "comctrl_sw0",
					  "comctrl_sw1",
					  "comctrl_sw2",
					  "comctrl_sw3",
					  "framegen0_primsync_on",
					  "framegen0_primsync_off",
					  "framegen0_overflow0_on",
					  "framegen0_overflow0_off",
					  "framegen0_underrun0_on",
					  "framegen0_underrun0_off",
					  "framegen0_threshold0_rise",
					  "framegen0_threshold0_fail",
					  "framegen0_overflow1_on",
					  "framegen0_overflow1_off",
					  "framegen0_underrun1_on",
					  "framegen0_underrun1_off",
					  "framegen0_threshold1_rise",
					  "framegen0_threshold1_fail",
					  "framegen1_primsync_on",
					  "framegen1_primsync_off",
					  "framegen1_overflow0_on",
					  "framegen1_overflow0_off",
					  "framegen1_underrun0_on",
					  "framegen1_underrun0_off",
					  "framegen1_threshold0_rise",
					  "framegen1_threshold0_fail",
					  "framegen1_overflow1_on",
					  "framegen1_overflow1_off",
					  "framegen1_underrun1_on",
					  "framegen1_underrun1_off",
					  "framegen1_threshold1_rise",
					  "framegen1_threshold1_fail";
			clocks = <&scmi_clk IMX952_CLK_DISP1PIX>,
				 <&scmi_clk IMX952_CLK_CGC_DISPSEERIS>,
				 <&scmi_clk IMX952_CLK_DISPAXI>,
				 <&scmi_clk IMX952_CLK_CGC_DISPOCRAM>,
				 <&clk_ldb_pll_pixel>,
				 <&scmi_clk IMX952_CLK_LDBPLL_VCO>;
			clock-names = "pix", "apb", "axi", "ocram", "ldb", "ldb_vco";
			power-domains = <&scmi_devpd IMX952_PD_DISPLAY>;
			nxp,blk-ctrl = <&dispmix_csr>;
			status = "disabled";

			ports {
				#address-cells = <1>;
				#size-cells = <0>;

				port@0 {
					reg = <0>;

					dpu_disp0_to_pixel_interleaver_disp0: endpoint {
						remote-endpoint = <&pixel_interleaver_disp0_to_dpu_disp0>;
					};
				};

				port@1 {
					reg = <1>;

					dpu_disp1_to_pixel_interleaver_disp1: endpoint {
						remote-endpoint = <&pixel_interleaver_disp1_to_dpu_disp1>;
					};
				};
			};
		};

		usb2: usb@4c200000 {
			compatible = "fsl,imx95-usb", "fsl,imx7d-usb", "fsl,imx27-usb";
			reg = <0x0 0x4c200000 0x0 0x200>;
			interrupts = <GIC_SPI 176 IRQ_TYPE_LEVEL_HIGH>,
				     <GIC_SPI 174 IRQ_TYPE_LEVEL_HIGH>;
			clocks = <&scmi_clk IMX952_CLK_CGC_HSIOUSB>,
				 <&scmi_clk IMX952_CLK_OSC32K>;
			clock-names = "usb_ctrl_root", "usb_wakeup";
			power-domains = <&scmi_devpd IMX952_PD_HSIO_TOP>;
			phys = <&usbphynop2>;
			fsl,usbmisc = <&usbmisc2 0>;
			status = "disabled";
		};

		usbmisc2: usbmisc@4c200200 {
			compatible = "fsl,imx95-usbmisc", "fsl,imx7d-usbmisc", "fsl,imx6q-usbmisc";
			#index-cells = <1>;
			reg = <0x0 0x4c200200 0x0 0x200>,
			      <0x0 0x4c010014 0x0 0x4>;
		};

		pcie0: pcie@4c300000 {
			compatible = "fsl,imx95-pcie";
			reg = <0 0x4c300000 0 0x10000>,
			      <0 0x60100000 0 0xfe00000>,
			      <0 0x4c360000 0 0x10000>,
			      <0 0x4c340000 0 0x4000>;
			reg-names = "dbi", "config", "atu", "app";
			ranges = <0x81000000 0x0 0x00000000 0x0 0x6ff00000 0 0x00100000>,
				 <0x82000000 0x0 0x10000000 0x9 0x10000000 0 0x80000000>;
			#address-cells = <3>;
			#size-cells = <2>;
			device_type = "pci";
			linux,pci-domain = <2>;
			/* Dev id(BIT[7:6)] 0x00,stream id(BIT[5:0]) 0x10~0x17 for pci0 */
			msi-map = <0x0 &its 0x10 0x1>,
				  <0x100 &its 0x11 0x7>;
			msi-map-mask = <0x1ff>; /* Suppose only 1 physic device connect */
			bus-range = <0x00 0xff>;
			num-lanes = <1>;
			num-viewport = <8>;
			interrupts = <GIC_SPI 310 IRQ_TYPE_LEVEL_HIGH>,
				     <GIC_SPI 311 IRQ_TYPE_LEVEL_HIGH>,
				     <GIC_SPI 310 IRQ_TYPE_LEVEL_HIGH>,
				     <GIC_SPI 310 IRQ_TYPE_LEVEL_HIGH>,
				     <GIC_SPI 310 IRQ_TYPE_LEVEL_HIGH>;
			interrupt-names = "msi", "dma", "aer", "intr", "pme";
			#interrupt-cells = <1>;
			interrupt-map-mask = <0 0 0 0x7>;
			interrupt-map = <0 0 0 1 &gic 0 0 GIC_SPI 306 IRQ_TYPE_LEVEL_HIGH>,
					<0 0 0 2 &gic 0 0 GIC_SPI 307 IRQ_TYPE_LEVEL_HIGH>,
					<0 0 0 3 &gic 0 0 GIC_SPI 308 IRQ_TYPE_LEVEL_HIGH>,
					<0 0 0 4 &gic 0 0 GIC_SPI 309 IRQ_TYPE_LEVEL_HIGH>;
			clocks = <&scmi_clk IMX952_CLK_CGC_HSIOPCIE>,
				 <&scmi_clk IMX952_CLK_HSIOPLL_VCO>,
				 <&scmi_clk IMX952_CLK_HSIOPLL>,
				 <&scmi_clk IMX952_CLK_HSIOPCIEAUX>,
				 <&hsio_blk_ctl 0>;
			clock-names = "pcie", "pcie_bus", "pcie_phy", "pcie_aux", "ref";
			assigned-clocks =<&scmi_clk IMX952_CLK_HSIOPLL_VCO>,
					 <&scmi_clk IMX952_CLK_HSIOPLL>,
					 <&scmi_clk IMX952_CLK_HSIOPCIEAUX>;
			assigned-clock-rates = <3600000000>, <100000000>, <10000000>;
			assigned-clock-parents = <0>, <0>,
						 <&scmi_clk IMX952_CLK_SYSPLL1_PFD1_DIV2>;
			power-domains = <&scmi_devpd IMX952_PD_HSIO_TOP>;
			fsl,max-link-speed = <3>;
			status = "disabled";
		};

		pcie0_ep: pcie-ep@4c300000 {
			compatible = "fsl,imx95-pcie-ep";
			reg = <0 0x4c300000 0 0x10000>,
			      <0 0x4c360000 0 0x1000>,
			      <0 0x4c320000 0 0x1000>,
			      <0 0x4c340000 0 0x4000>,
			      <0 0x4c370000 0 0x10000>,
			      <0x9 0 1 0>;
			reg-names = "dbi","atu", "dbi2", "app", "dma", "addr_space";
			num-lanes = <1>;
			msi-map = <0x0 &its 0x11 0x1>;
			interrupts = <GIC_SPI 311 IRQ_TYPE_LEVEL_HIGH>;
			interrupt-names = "dma";
			clocks = <&scmi_clk IMX952_CLK_CGC_HSIOPCIE>,
				 <&scmi_clk IMX952_CLK_HSIOPLL_VCO>,
				 <&scmi_clk IMX952_CLK_HSIOPLL>,
				 <&scmi_clk IMX952_CLK_HSIOPCIEAUX>,
				 <&hsio_blk_ctl 0>;
			clock-names = "pcie", "pcie_bus", "pcie_phy", "pcie_aux", "ref";
			assigned-clocks =<&scmi_clk IMX952_CLK_HSIOPLL_VCO>,
					 <&scmi_clk IMX952_CLK_HSIOPLL>,
					 <&scmi_clk IMX952_CLK_HSIOPCIEAUX>;
			assigned-clock-rates = <3600000000>, <100000000>, <10000000>;
			assigned-clock-parents = <0>, <0>,
						 <&scmi_clk IMX952_CLK_SYSPLL1_PFD1_DIV2>;
			power-domains = <&scmi_devpd IMX952_PD_HSIO_TOP>;
			fsl,max-link-speed = <3>;
			status = "disabled";
		};

		mali: gpu@4d900000 {
			compatible = "arm,mali-valhall", "nxp,imx952-mali";
			reg = <0 0x4d900000 0 0x480000>;
			reg-names = "gpu_base";
			interrupts = <GIC_SPI 288 IRQ_TYPE_LEVEL_HIGH>,
				     <GIC_SPI 289 IRQ_TYPE_LEVEL_HIGH>,
				     <GIC_SPI 290 IRQ_TYPE_LEVEL_HIGH>;
			interrupt-names = "gpu", "job", "mmu";
			clocks = <&scmi_clk IMX952_CLK_GPU>;
			clock-names = "gpu";
			power-domains = <&scmi_devpd IMX952_PD_GPU>, <&scmi_perf IMX952_PERF_GPU>;
			power-domain-names = "gpumix", "gpuperf";
			operating-points-v2 = <&gpu_opp_table>;
			#cooling-cells = <2>;
			simple_power: power_model@0 {
			    compatible = "arm,mali-simple-power-model";
			    static-coefficient = <59073>;
			    dynamic-coefficient = <1013>;
			    reference_voltage = <920>;
			    ts = <20000 2000 (-20) 2>;
			    thermal-zone = "ana-thermal";
			};

			ipa_power:power_model@1 {
			    compatible = "arm,mali-tvax-power-model";
			    reference_voltage = <920>;
			};
		};

		netcmix_blk_ctrl: syscon@4c810000 {
			compatible = "nxp,imx95-netcmix-blk-ctrl", "syscon";
			reg = <0x0 0x4c810000 0x0 0x8>;
			#clock-cells = <1>;
			clocks = <&scmi_clk IMX952_CLK_CGC_NETC>;
			power-domains = <&scmi_devpd IMX952_PD_NETC>;
		};

		netc_blk_ctrl: netc-blk-ctrl@4cd20000 {
			compatible = "nxp,imx952-netc-blk-ctrl";
			reg = <0x0 0x4cd20000 0x0 0x10000>,
			      <0x0 0x4cd30000 0x0 0x10000>,
			      <0x0 0x4c81000c 0x0 0x1c>;
			reg-names = "ierb", "prb", "netcmix";
			#address-cells = <2>;
			#size-cells = <2>;
			ranges;
			power-domains = <&scmi_devpd IMX952_PD_NETC>;
			assigned-clocks = <&scmi_clk IMX952_CLK_ENET>,
					  <&scmi_clk IMX952_CLK_ENETREF>;
			assigned-clock-parents = <&scmi_clk IMX952_CLK_SYSPLL1_PFD1>,
						 <&scmi_clk IMX952_CLK_SYSPLL1_PFD0>;
			assigned-clock-rates = <266666666>, <250000000>;
			clocks = <&scmi_clk IMX952_CLK_CGC_NETC>;
			clock-names = "ipg";
			status = "disabled";

			netc_bus0: pcie@4ca00000 {
				compatible = "pci-host-ecam-generic";
				reg = <0x0 0x4ca00000 0x0 0x100000>;
				#address-cells = <3>;
				#size-cells = <2>;
				device_type = "pci";
				linux,pci-domain = <0>;
				bus-range = <0x0 0x0>;
				msi-map = <0x000 &its 0x60 0x1>, //ENETC0 PF
					  <0x001 &its 0x62 0x1>, //NETC Timer
					  <0x002 &its 0x63 0x1>, //EMDIO
					  <0x040 &its 0x64 0x1>; //ENETC0 VF
					  /* ENETC0 BAR0 - non-prefetchable memory */
				ranges = <0x82000000 0x0 0x4cc00000  0x0 0x4cc00000  0x0 0x40000
					  /* Timer and EMDIO BAR0/2 and ENETC0 VF BAR0 - non-prefetchable memory */
					  0x82000000 0x0 0x4cc80000  0x0 0x4cc80000  0x0 0x70000
					  /* ENETC0 VF BAR2 - non-prefetchable memory */
					  0x82000000 0x0 0x4cd00000  0x0 0x4cd00000  0x0 0x10000>;
				#interrupt-cells = <1>;
				interrupt-map-mask = <0 0 0 7>;
				interrupt-map = <0000 0 0 1 &gic 0 0
						 GIC_SPI 304 IRQ_TYPE_LEVEL_HIGH>;
				status = "disabled";

				netc_enetc0: ethernet@0,0 {
					compatible = "pci1131,e101";
					reg = <0x00000 0 0 0 0>;
					clocks = <&scmi_clk IMX952_CLK_ENETREF>;
					clock-names = "ref";
					nvmem-cells = <&eth_mac0>;
					nvmem-cell-names = "mac-address";
					status = "disabled";
				};

				netc_timer: ptp-timer@0,1 {
					compatible = "pci1131,ee02";
					reg = <0x00100 0 0 0 0>;
					status = "disabled";
				};

				netc_emdio: mdio@0,2 {
					compatible = "pci1131,ee00";
					reg = <0x00200 0 0 0 0>;
					#address-cells = <1>;
					#size-cells = <0>;
					status = "disabled";
				};

				rcec@1,0 {
					reg = <0x00800 0 0 0 0>;
					interrupts = <1>;
				};
			};

			netc_bus1: pcie@4cb00000 {
				compatible = "pci-host-ecam-generic";
				reg = <0x0 0x4cb00000 0x0 0x100000>;
				#address-cells = <3>;
				#size-cells = <2>;
				device_type = "pci";
				linux,pci-domain = <1>;
				bus-range = <0x1 0x1>;
				msi-map = <0x100 &its 0x61 0x1>, //ENETC1 PF
					  <0x140 &its 0x65 0x1>; //ENETC1 VF
					  /* ENETC1 BAR0 - non-prefetchable memory */
				ranges = <0x82000000 0x0 0x4cc40000  0x0 0x4cc40000  0x0 0x40000
					  /* ENETC1: VF BAR0 - non-prefetchable memory */
					  0x82000000 0x0 0x4ccf0000  0x0 0x4ccf0000  0x0 0x10000
					  /* ENETC1: VF BAR2 - non-prefetchable memory */
					  0x82000000 0x0 0x4cd10000  0x0 0x4cd10000  0x0 0x10000>;
				#interrupt-cells = <1>;
				interrupt-map-mask = <0 0 0 7>;
				interrupt-map = <0000 0 0 1 &gic 0 0
						 GIC_SPI 305 IRQ_TYPE_LEVEL_HIGH>;
				status = "disabled";

				netc_enetc1: ethernet@0,0 {
					compatible = "pci1131,e101";
					reg = <0x10000 0 0 0 0>;
					ptp-timer = <&netc_timer>;
					nvmem-cells = <&eth_mac1>;
					nvmem-cell-names = "mac-address";
					status = "disabled";
				};

				rcec@1,0 {
					reg = <0x10800 0 0 0 0>;
					interrupts = <1>;
				};
			};
		};

		sai2: sai@4c880000 {
			compatible = "fsl,imx952-sai", "fsl,imx95-sai";
			reg = <0x0 0x4c880000 0x0 0x10000>;
			interrupts = <GIC_SPI 169 IRQ_TYPE_LEVEL_HIGH>;
			clocks = <&scmi_clk IMX952_CLK_BUSNETCMIX>, <&clk_dummy>,
				 <&scmi_clk IMX952_CLK_SAI2>, <&clk_dummy>,
				 <&clk_dummy>;
			clock-names = "bus", "mclk0", "mclk1", "mclk2", "mclk3";
			dmas = <&edma2 59 0 FSL_EDMA_RX>, <&edma2 58 0 0>;
			dma-names = "rx", "tx";
			#sound-dai-cells = <0>;
			power-domains = <&scmi_devpd IMX952_PD_NETC>;
			status = "disabled";
		};

		ddr-pmu@4e090dc0 {
			compatible = "fsl,imx95-ddr-pmu", "fsl,imx93-ddr-pmu";
			reg = <0x0 0x4e090dc0 0x0 0x200>;
			interrupts = <GIC_SPI 91 IRQ_TYPE_LEVEL_HIGH>;
		};

		vpuenc: vpuenc@4c460000 {
			compatible = "nxp,coda980-vpu";
			reg = <0x0 0x4c460000 0x0 0x10000>;
			interrupts = <GIC_SPI 303 IRQ_TYPE_LEVEL_HIGH>;
			clocks = <&scmi_clk IMX952_CLK_CGC_VPUENC>, <&scmi_clk IMX952_CLK_VPUAPB>;
			clock-names = "vpu", "vpuapb";
			power-domains = <&scmi_devpd IMX952_PD_VPU>;
		};

		vpu0: vpu@4c4b0000 {
			compatible = "nxp,wave511-vpu";
			reg = <0x0 0x4c4b0000 0x0 0x400>;
			interrupts = <GIC_SPI 299 IRQ_TYPE_LEVEL_HIGH>;
			clocks = <&scmi_clk IMX952_CLK_CGC_VPUDEC>, <&scmi_clk IMX952_CLK_VPUAPB>;
			clock-names = "vpu", "vpuapb";
			power-domains = <&scmi_devpd IMX952_PD_VPU>;
			cnm,ctrl = <&vpuctrl>;
		};

		vpu1: vpu@4c4c0000 {
			compatible = "nxp,wave511-vpu";
			reg = <0x0 0x4c4c0000 0x0 0x400>;
			interrupts = <GIC_SPI 300 IRQ_TYPE_LEVEL_HIGH>;
			clocks = <&scmi_clk IMX952_CLK_CGC_VPUDEC>, <&scmi_clk IMX952_CLK_VPUAPB>;
			clock-names = "vpu", "vpuapb";
			power-domains = <&scmi_devpd IMX952_PD_VPU>;
			cnm,ctrl = <&vpuctrl>;
			status = "disabled";
		};

		vpu2: vpu@4c4d0000 {
			compatible = "nxp,wave511-vpu";
			reg = <0x0 0x4c4d0000 0x0 0x400>;
			interrupts = <GIC_SPI 301 IRQ_TYPE_LEVEL_HIGH>;
			clocks = <&scmi_clk IMX952_CLK_CGC_VPUDEC>, <&scmi_clk IMX952_CLK_VPUAPB>;
			clock-names = "vpu", "vpuapb";
			power-domains = <&scmi_devpd IMX952_PD_VPU>;
			cnm,ctrl = <&vpuctrl>;
			status = "disabled";
		};

		vpu3: vpu@4c4e0000 {
			compatible = "nxp,wave511-vpu";
			reg = <0x0 0x4c4e0000 0x0 0x400>;
			interrupts = <GIC_SPI 302 IRQ_TYPE_LEVEL_HIGH>;
			clocks = <&scmi_clk IMX952_CLK_CGC_VPUDEC>, <&scmi_clk IMX952_CLK_VPUAPB>;
			clock-names = "vpu", "vpuapb";
			power-domains = <&scmi_devpd IMX952_PD_VPU>;
			cnm,ctrl = <&vpuctrl>;
			status = "disabled";
		};

		vpuctrl: vpu-ctrl@4c4f0000 {
			compatible = "nxp,wave511-vpu-ctrl";
			reg = <0x0 0x4c4f0000 0x0 0x400>;
			clocks = <&scmi_clk IMX952_CLK_CGC_VPUDEC>, <&scmi_clk IMX952_CLK_VPUAPB>;
			power-domains = <&scmi_devpd IMX952_PD_VPU>;
		};

		jpegdec: jpegdec@4c500000 {
			compatible = "nxp,imx8qxp-jpgdec";
			reg = <0x0 0x4C500000 0x0 0x00050000>;
			interrupts = <GIC_SPI 295 IRQ_TYPE_LEVEL_HIGH>,
				     <GIC_SPI 296 IRQ_TYPE_LEVEL_HIGH>,
				     <GIC_SPI 297 IRQ_TYPE_LEVEL_HIGH>,
				     <GIC_SPI 298 IRQ_TYPE_LEVEL_HIGH>;
			clocks = <&scmi_clk IMX952_CLK_CGC_VPUJPEGDEC>,
				 <&scmi_clk IMX952_CLK_VPUAPB>;
			power-domains = <&scmi_devpd IMX952_PD_VPU>;
		};

		jpegenc: jpegenc@4c550000 {
			compatible = "nxp,imx8qxp-jpgenc";
			reg = <0x0 0x4C550000 0x0 0x00050000>;
			interrupts = <GIC_SPI 291 IRQ_TYPE_LEVEL_HIGH>,
				     <GIC_SPI 292 IRQ_TYPE_LEVEL_HIGH>,
				     <GIC_SPI 293 IRQ_TYPE_LEVEL_HIGH>,
				     <GIC_SPI 294 IRQ_TYPE_LEVEL_HIGH>;
			clocks = <&scmi_clk IMX952_CLK_CGC_VPUJPEGENC>,
				 <&scmi_clk IMX952_CLK_VPUAPB>;
			power-domains = <&scmi_devpd IMX952_PD_VPU>;
		};

		neutron_core: neutron-remoteproc@4ab00000 {
			compatible = "fsl,imx95-neutron-rproc";
			reg = <0x0 0x4ab00000 0x0 0x4>;
			power-domains = <&scmi_devpd IMX952_PD_NPU>;
		};

		neutron: neutron@4ab00004 {
			compatible = "fsl,imx95-neutron";
			reg = <0x0 0x4ab00004 0x0 0x400>;
			fsl,neutron-rproc = <&neutron_core>;
			interrupts = <GIC_SPI 318 IRQ_TYPE_LEVEL_HIGH>;
			clocks = <&scmi_clk IMX952_CLK_NPU>,
				 <&scmi_clk IMX952_CLK_NPUAPB>,
				 <&scmi_clk IMX952_CLK_CGC_NPU>;
			clock-names = "npu", "npu_apb, npu_cgc";
			power-domains = <&scmi_devpd IMX952_PD_NPU>;
		};
	};

	ele_if0: secure-enclave-0 {
		compatible = "fsl,imx95-se";
		mbox-names = "tx", "rx";
		mboxes = <&elemu3 0 0>,
			 <&elemu3 1 0>;
	};

	v2x_dbg: secure-enclave-1 {
		compatible = "fsl,imx95-se";
		mbox-names = "tx", "rx";
		mboxes = <&v2x_mu 0 0>,
			<&v2x_mu 1 0>;
	};

	v2x_sv0: secure-enclave-2 {
		compatible = "fsl,imx95-se";
		mbox-names = "tx", "rx";
		mboxes = <&v2x_mu0 0 0>,
			<&v2x_mu0 1 0>;
	};

	v2x_she: secure-enclave-3 {
		compatible = "fsl,imx95-se";
		mbox-names = "tx", "rx";
		mboxes = <&v2x_mu2 0 0>,
			<&v2x_mu2 1 0>;
		status = "disabled";
	};

	v2x_sg0: secure-enclave-4 {
		compatible = "fsl,imx95-se";
		mboxes = <&v2x_mu3 0 0>,
			<&v2x_mu3 1 0>;
		mbox-names = "tx", "rx";
	};

	v2x_sg1: secure-enclave-5 {
		compatible = "fsl,imx95-se";
		mboxes = <&v2x_mu4 0 0>,
			<&v2x_mu4 1 0>;
		mbox-names = "tx", "rx";
	};

};
